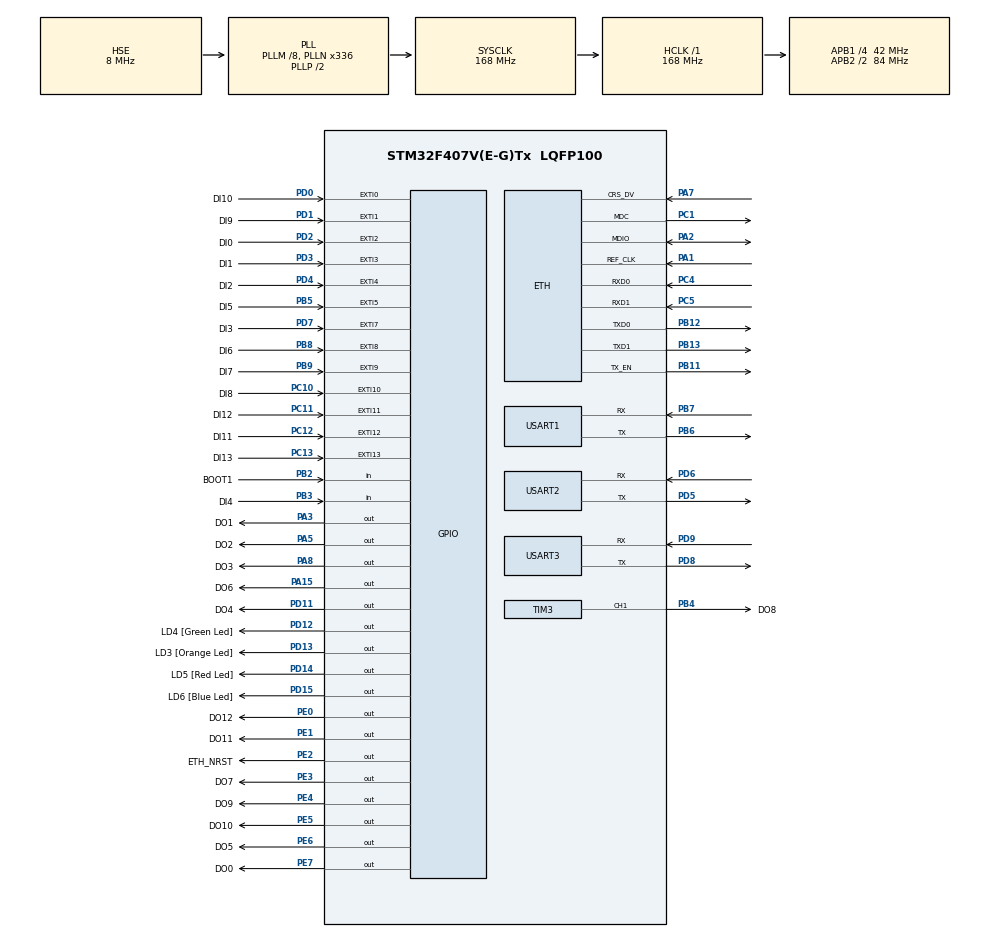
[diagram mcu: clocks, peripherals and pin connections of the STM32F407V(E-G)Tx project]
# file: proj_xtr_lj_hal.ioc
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Dma.Request0=USART1_RX
Dma.Request1=USART1_TX
Dma.Request2=USART2_RX
Dma.Request3=USART2_TX
Dma.Request4=USART3_RX
Dma.Request5=USART3_TX
Dma.USART1_RX.0.Direction=DMA_PERIPH_TO_MEMORY
Dma.USART1_RX.0.FIFOMode=DMA_FIFOMODE_DISABLE
Dma.USART1_RX.0.Instance=DMA2_Stream2
Dma.USART1_RX.0.MemDataAlignment=DMA_MDATAALIGN_BYTE
Dma.USART1_RX.0.MemInc=DMA_MINC_ENABLE
Dma.USART1_RX.0.Mode=DMA_NORMAL
Dma.USART1_RX.0.PeriphDataAlignment=DMA_PDATAALIGN_BYTE
Dma.USART1_RX.0.PeriphInc=DMA_PINC_DISABLE
Dma.USART1_RX.0.Priority=DMA_PRIORITY_LOW
Dma.USART1_TX.1.Direction=DMA_MEMORY_TO_PERIPH
Dma.USART1_TX.1.FIFOMode=DMA_FIFOMODE_DISABLE
Dma.USART1_TX.1.Instance=DMA2_Stream7
Dma.USART1_TX.1.MemDataAlignment=DMA_MDATAALIGN_BYTE
Dma.USART1_TX.1.MemInc=DMA_MINC_ENABLE
Dma.USART1_TX.1.Mode=DMA_NORMAL
Dma.USART1_TX.1.PeriphDataAlignment=DMA_PDATAALIGN_BYTE
Dma.USART1_TX.1.PeriphInc=DMA_PINC_DISABLE
Dma.USART1_TX.1.Priority=DMA_PRIORITY_LOW
Dma.USART2_RX.2.Direction=DMA_PERIPH_TO_MEMORY
Dma.USART2_RX.2.FIFOMode=DMA_FIFOMODE_DISABLE
Dma.USART2_RX.2.Instance=DMA1_Stream5
Dma.USART2_RX.2.MemDataAlignment=DMA_MDATAALIGN_BYTE
Dma.USART2_RX.2.MemInc=DMA_MINC_ENABLE
Dma.USART2_RX.2.Mode=DMA_NORMAL
Dma.USART2_RX.2.PeriphDataAlignment=DMA_PDATAALIGN_BYTE
Dma.USART2_RX.2.PeriphInc=DMA_PINC_DISABLE
Dma.USART2_RX.2.Priority=DMA_PRIORITY_LOW
Dma.USART2_TX.3.Direction=DMA_MEMORY_TO_PERIPH
Dma.USART2_TX.3.FIFOMode=DMA_FIFOMODE_DISABLE
Dma.USART2_TX.3.Instance=DMA1_Stream6
Dma.USART2_TX.3.MemDataAlignment=DMA_MDATAALIGN_BYTE
Dma.USART2_TX.3.MemInc=DMA_MINC_ENABLE
Dma.USART2_TX.3.Mode=DMA_NORMAL
Dma.USART2_TX.3.PeriphDataAlignment=DMA_PDATAALIGN_BYTE
Dma.USART2_TX.3.PeriphInc=DMA_PINC_DISABLE
Dma.USART2_TX.3.Priority=DMA_PRIORITY_LOW
Dma.USART3_RX.4.Direction=DMA_PERIPH_TO_MEMORY
Dma.USART3_RX.4.FIFOMode=DMA_FIFOMODE_DISABLE
Dma.USART3_RX.4.Instance=DMA1_Stream1
Dma.USART3_RX.4.MemDataAlignment=DMA_MDATAALIGN_BYTE
Dma.USART3_RX.4.MemInc=DMA_MINC_ENABLE
Dma.USART3_RX.4.Mode=DMA_NORMAL
Dma.USART3_RX.4.PeriphDataAlignment=DMA_PDATAALIGN_BYTE
Dma.USART3_RX.4.PeriphInc=DMA_PINC_DISABLE
Dma.USART3_RX.4.Priority=DMA_PRIORITY_LOW
Dma.USART3_TX.5.Direction=DMA_MEMORY_TO_PERIPH
Dma.USART3_TX.5.FIFOMode=DMA_FIFOMODE_DISABLE
Dma.USART3_TX.5.Instance=DMA1_Stream3
Dma.USART3_TX.5.MemDataAlignment=DMA_MDATAALIGN_BYTE
Dma.USART3_TX.5.MemInc=DMA_MINC_ENABLE
Dma.USART3_TX.5.Mode=DMA_NORMAL
Dma.USART3_TX.5.PeriphDataAlignment=DMA_PDATAALIGN_BYTE
Dma.USART3_TX.5.PeriphInc=DMA_PINC_DISABLE
Dma.USART3_TX.5.Priority=DMA_PRIORITY_LOW
ETH.MediaInterface=ETH_MEDIA_INTERFACE_RMII
ETH.PHY_Name_RMII=LAN8742A_PHY_ADDRESS
ETH.PhyAddress=1
FREERTOS.Tasks01=defaultTask,24,128,StartDefaultTask,Default,NULL,Dynamic,NULL,NULL;Blink,8,128,StartBlink,Default,NULL,Dynamic,NULL,NULL;KeepState,8,128,StartKeepState,Default,NULL,Dynamic,NULL,NULL
FREERTOS.configENABLE_FPU=1
Mcu.Family=STM32F4
Mcu.Name=STM32F407V(E-G)Tx
Mcu.Package=LQFP100
NVIC.DMA1_Stream1_IRQn=true\:0\:0\:false\:false\:true\:true\:false\:true
NVIC.DMA1_Stream3_IRQn=true\:0\:0\:false\:false\:true\:true\:false\:true
NVIC.DMA1_Stream5_IRQn=true\:0\:0\:false\:false\:true\:true\:false\:true
NVIC.DMA1_Stream6_IRQn=true\:0\:0\:false\:false\:true\:true\:false\:true
NVIC.DMA2_Stream2_IRQn=true\:0\:0\:false\:false\:true\:true\:false\:true
NVIC.DMA2_Stream7_IRQn=true\:0\:0\:false\:false\:true\:true\:false\:true
NVIC.EXTI0_IRQn=true\:1\:0\:true\:false\:true\:false\:true\:true
NVIC.EXTI15_10_IRQn=true\:1\:0\:true\:false\:true\:false\:true\:true
NVIC.EXTI1_IRQn=true\:1\:0\:true\:false\:true\:false\:true\:true
NVIC.EXTI2_IRQn=true\:2\:0\:true\:false\:true\:false\:true\:true
NVIC.EXTI3_IRQn=true\:2\:0\:true\:false\:true\:false\:true\:true
NVIC.EXTI4_IRQn=true\:2\:0\:true\:false\:true\:false\:true\:true
NVIC.EXTI9_5_IRQn=true\:2\:0\:true\:false\:true\:false\:true\:true
NVIC.PriorityGroup=NVIC_PRIORITYGROUP_4
NVIC.TIM3_IRQn=true\:0\:0\:true\:false\:true\:false\:true\:true
NVIC.TIM8_TRG_COM_TIM14_IRQn=true\:0\:0\:false\:false\:true\:false\:false\:true
NVIC.TimeBase=TIM8_TRG_COM_TIM14_IRQn
NVIC.TimeBaseIP=TIM14
NVIC.USART1_IRQn=true\:1\:0\:true\:false\:true\:false\:true\:true
NVIC.USART2_IRQn=true\:1\:0\:true\:false\:true\:false\:true\:true
NVIC.USART3_IRQn=true\:1\:0\:true\:false\:true\:false\:true\:true
PA1.Mode=RMII
PA1.Signal=ETH_REF_CLK
PA13.GPIO_Label=SWDIO
PA13.Mode=Serial_Wire
PA13.Signal=SYS_JTMS-SWDIO
PA14.GPIO_Label=SWCLK
PA14.Mode=Serial_Wire
PA14.Signal=SYS_JTCK-SWCLK
PA15.GPIO_Label=DO6
PA15.PinState=GPIO_PIN_SET
PA15.Signal=GPIO_Output
PA2.Mode=RMII
PA2.Signal=ETH_MDIO
PA3.GPIO_Label=DO1
PA3.PinState=GPIO_PIN_SET
PA3.Signal=GPIO_Output
PA5.GPIO_Label=DO2
PA5.PinState=GPIO_PIN_SET
PA5.Signal=GPIO_Output
PA7.Mode=RMII
PA7.Signal=ETH_CRS_DV
PA8.GPIO_Label=DO3
PA8.PinState=GPIO_PIN_SET
PA8.Signal=GPIO_Output
PB11.Mode=RMII
PB11.Signal=ETH_TX_EN
PB12.Mode=RMII
PB12.Signal=ETH_TXD0
PB13.Mode=RMII
PB13.Signal=ETH_TXD1
PB2.GPIO_Label=BOOT1
PB2.GPIO_Mode=GPIO_MODE_INPUT
PB2.GPIO_PuPd=GPIO_NOPULL
PB2.Signal=GPIO_Input
PB3.GPIO_Label=DI4
PB3.GPIO_PuPd=GPIO_PULLDOWN
PB3.Signal=GPIO_Input
PB4.GPIO_Label=DO8
PB4.GPIO_PuPd=GPIO_PULLUP
PB4.GPIO_Speed=GPIO_SPEED_FREQ_HIGH
PB4.Signal=S_TIM3_CH1
PB5.GPIO_Label=DI5
PB5.GPIO_ModeDefaultEXTI=GPIO_MODE_IT_RISING_FALLING
PB5.GPIO_PuPd=GPIO_PULLDOWN
PB5.Signal=GPXTI5
PB6.Mode=Asynchronous
PB6.Signal=USART1_TX
PB7.Mode=Asynchronous
PB7.Signal=USART1_RX
PB8.GPIO_Label=DI6
PB8.GPIO_ModeDefaultEXTI=GPIO_MODE_IT_RISING_FALLING
PB8.GPIO_PuPd=GPIO_PULLDOWN
PB8.Signal=GPXTI8
PB9.GPIO_Label=DI7
PB9.GPIO_ModeDefaultEXTI=GPIO_MODE_IT_RISING_FALLING
PB9.GPIO_PuPd=GPIO_PULLDOWN
PB9.Signal=GPXTI9
PC1.Mode=RMII
PC1.Signal=ETH_MDC
PC10.GPIO_Label=DI8
PC10.GPIO_ModeDefaultEXTI=GPIO_MODE_IT_RISING
PC10.GPIO_PuPd=GPIO_PULLDOWN
PC10.Signal=GPXTI10
PC11.GPIO_Label=DI12
PC11.GPIO_ModeDefaultEXTI=GPIO_MODE_IT_RISING
PC11.GPIO_PuPd=GPIO_PULLDOWN
PC11.Signal=GPXTI11
PC12.GPIO_Label=DI11
PC12.GPIO_ModeDefaultEXTI=GPIO_MODE_IT_RISING
PC12.GPIO_PuPd=GPIO_PULLDOWN
PC12.Signal=GPXTI12
PC13-ANTI_TAMP.GPIO_Label=DI13
PC13-ANTI_TAMP.GPIO_ModeDefaultEXTI=GPIO_MODE_IT_RISING
PC13-ANTI_TAMP.GPIO_PuPd=GPIO_PULLDOWN
PC13-ANTI_TAMP.Signal=GPXTI13
PC14-OSC32_IN.GPIO_Label=PC14-OSC32_IN
PC14-OSC32_IN.Mode=LSE-External-Oscillator
PC14-OSC32_IN.Signal=RCC_OSC32_IN
PC15-OSC32_OUT.GPIO_Label=PC15-OSC32_OUT
PC15-OSC32_OUT.Mode=LSE-External-Oscillator
PC15-OSC32_OUT.Signal=RCC_OSC32_OUT
PC4.Mode=RMII
PC4.Signal=ETH_RXD0
PC5.Mode=RMII
PC5.Signal=ETH_RXD1
PD0.GPIO_Label=DI10
PD0.GPIO_ModeDefaultEXTI=GPIO_MODE_IT_RISING
PD0.GPIO_PuPd=GPIO_PULLDOWN
PD0.Signal=GPXTI0
PD1.GPIO_Label=DI9
PD1.GPIO_ModeDefaultEXTI=GPIO_MODE_IT_RISING
PD1.GPIO_PuPd=GPIO_PULLDOWN
PD1.Signal=GPXTI1
PD11.GPIO_Label=DO4
PD11.PinState=GPIO_PIN_SET
PD11.Signal=GPIO_Output
PD12.GPIO_Label=LD4 [Green Led]
PD12.GPIO_PuPd=GPIO_NOPULL
PD12.GPIO_Speed=GPIO_SPEED_FREQ_LOW
PD12.Signal=GPIO_Output
PD13.GPIO_Label=LD3 [Orange Led]
PD13.GPIO_PuPd=GPIO_NOPULL
PD13.GPIO_Speed=GPIO_SPEED_FREQ_LOW
PD13.Signal=GPIO_Output
PD14.GPIO_Label=LD5 [Red Led]
PD14.GPIO_PuPd=GPIO_NOPULL
PD14.GPIO_Speed=GPIO_SPEED_FREQ_LOW
PD14.Signal=GPIO_Output
PD15.GPIO_Label=LD6 [Blue Led]
PD15.GPIO_PuPd=GPIO_NOPULL
PD15.GPIO_Speed=GPIO_SPEED_FREQ_LOW
PD15.Signal=GPIO_Output
PD2.GPIO_Label=DI0
PD2.GPIO_ModeDefaultEXTI=GPIO_MODE_IT_RISING_FALLING
PD2.GPIO_PuPd=GPIO_PULLDOWN
PD2.Signal=GPXTI2
PD3.GPIO_Label=DI1
PD3.GPIO_ModeDefaultEXTI=GPIO_MODE_IT_RISING_FALLING
PD3.GPIO_PuPd=GPIO_PULLDOWN
PD3.Signal=GPXTI3
PD4.GPIO_Label=DI2
PD4.GPIO_ModeDefaultEXTI=GPIO_MODE_IT_RISING_FALLING
PD4.GPIO_PuPd=GPIO_PULLDOWN
PD4.Signal=GPXTI4
PD5.Mode=Asynchronous
PD5.Signal=USART2_TX
PD6.Mode=Asynchronous
PD6.Signal=USART2_RX
PD7.GPIO_Label=DI3
PD7.GPIO_ModeDefaultEXTI=GPIO_MODE_IT_RISING_FALLING
PD7.GPIO_PuPd=GPIO_PULLDOWN
PD7.Signal=GPXTI7
PD8.Mode=Asynchronous
PD8.Signal=USART3_TX
PD9.Mode=Asynchronous
PD9.Signal=USART3_RX
PE0.GPIO_Label=DO12
PE0.PinState=GPIO_PIN_SET
PE0.Signal=GPIO_Output
PE1.GPIO_Label=DO11
PE1.PinState=GPIO_PIN_SET
PE1.Signal=GPIO_Output
PE2.GPIO_Label=ETH_NRST
PE2.PinState=GPIO_PIN_SET
PE2.Signal=GPIO_Output
PE3.GPIO_Label=DO7
PE3.PinState=GPIO_PIN_SET
PE3.Signal=GPIO_Output
PE4.GPIO_Label=DO9
PE4.PinState=GPIO_PIN_SET
PE4.Signal=GPIO_Output
PE5.GPIO_Label=DO10
PE5.PinState=GPIO_PIN_SET
PE5.Signal=GPIO_Output
PE6.GPIO_Label=DO5
PE6.PinState=GPIO_PIN_SET
PE6.Signal=GPIO_Output
PE7.GPIO_Label=DO0
PE7.PinState=GPIO_PIN_SET
PE7.Signal=GPIO_Output
PH0-OSC_IN.GPIO_Label=PH0-OSC_IN
PH0-OSC_IN.Mode=HSE-External-Oscillator
PH0-OSC_IN.Signal=RCC_OSC_IN
PH1-OSC_OUT.GPIO_Label=PH1-OSC_OUT
PH1-OSC_OUT.Mode=HSE-External-Oscillator
PH1-OSC_OUT.Signal=RCC_OSC_OUT
ProjectManager.HeapSize=0x200
ProjectManager.StackSize=0x400
ProjectManager.TargetToolchain=MDK-ARM V5.27
RCC.48MHZClocksFreq_Value=48000000
RCC.AHBFreq_Value=168000000
RCC.APB1CLKDivider=RCC_HCLK_DIV4
RCC.APB1Freq_Value=42000000
RCC.APB1TimFreq_Value=84000000
RCC.APB2CLKDivider=RCC_HCLK_DIV2
RCC.APB2Freq_Value=84000000
RCC.APB2TimFreq_Value=168000000
RCC.CortexFreq_Value=168000000
RCC.HCLKFreq_Value=168000000
RCC.HSE_VALUE=8000000
RCC.HSI_VALUE=16000000
RCC.PLLM=8
RCC.PLLN=336
RCC.PLLQ=7
RCC.PLLSourceVirtual=RCC_PLLSOURCE_HSE
RCC.SYSCLKFreq_VALUE=168000000
RCC.SYSCLKSource=RCC_SYSCLKSOURCE_PLLCLK
RCC.VCOOutputFreq_Value=336000000
SH.S_TIM3_CH1.0=TIM3_CH1,PWM Generation1 CH1
TIM3.Channel-PWM\ Generation1\ CH1=TIM_CHANNEL_1
TIM3.OCPolarity_1=TIM_OCPOLARITY_LOW
USART1.VirtualMode=VM_ASYNC
USART2.VirtualMode=VM_ASYNC
USART3.VirtualMode=VM_ASYNC
VP_FREERTOS_VS_CMSIS_V2.Mode=CMSIS_V2
VP_SYS_VS_tim14.Mode=TIM14
VP_TIM3_VS_ClockSourceINT.Mode=Internal
board=STM32F407G-DISC1

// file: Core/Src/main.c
/* USER CODE BEGIN Header */
/**
  ******************************************************************************
  * @file           : main.c
  * @brief          : Main program body
  ******************************************************************************
  * @attention
  *
  * <h2><center>&copy; Copyright (c) 2020 STMicroelectronics.
  * All rights reserved.</center></h2>
  *
  * This software component is licensed by ST under Ultimate Liberty license
  * SLA0044, the "License"; You may not use this file except in compliance with
  * the License. You may obtain a copy of the License at:
  *                             www.st.com/SLA0044
  *
  ******************************************************************************
  */
/* USER CODE END Header */
#include "main.h"
#include "cmsis_os.h"

ETH_HandleTypeDef heth;

TIM_HandleTypeDef htim3;

UART_HandleTypeDef huart1;
UART_HandleTypeDef huart2;
UART_HandleTypeDef huart3;
DMA_HandleTypeDef hdma_usart1_rx;
DMA_HandleTypeDef hdma_usart1_tx;
DMA_HandleTypeDef hdma_usart2_rx;
DMA_HandleTypeDef hdma_usart2_tx;
DMA_HandleTypeDef hdma_usart3_rx;
DMA_HandleTypeDef hdma_usart3_tx;

/* Definitions for defaultTask */
osThreadId_t defaultTaskHandle;
const osThreadAttr_t defaultTask_attributes = {
  .name = "defaultTask",
  .priority = (osPriority_t) osPriorityNormal,
  .stack_size = 128 * 4
};
/* Definitions for Blink */
osThreadId_t BlinkHandle;
const osThreadAttr_t Blink_attributes = {
  .name = "Blink",
  .priority = (osPriority_t) osPriorityLow,
  .stack_size = 128 * 4
};
/* Definitions for KeepState */
osThreadId_t KeepStateHandle;
const osThreadAttr_t KeepState_attributes = {
  .name = "KeepState",
  .priority = (osPriority_t) osPriorityLow,
  .stack_size = 128 * 4
};
/* USER CODE BEGIN PV */

uint8_t previous_command = 0;
uint8_t current_command = 0;
uint8_t UART_send_buffer[16];
uint8_t UART_recv_buffer[16];
uint8_t UART_field_buffer[16];
uint8_t ch;
int uart_recv_cnt = 0;
xSemaphoreHandle uart_A1_xSemaphore = NULL;
xSemaphoreHandle exti_xSemaphore = NULL;
portTickType time_origin;
volatile int pwm_count = 0;

osThreadId_t FieldHandle;
const osThreadAttr_t field_attributes = {
  .name = "FieldTask",
  .priority = (osPriority_t) osPriorityLow,
  .stack_size = 128 * 4
};
/* USER CODE END PV */

//xTaskHandle field_xHandle = NULL;

void SystemClock_Config(void);
static void MX_GPIO_Init(void);
static void MX_DMA_Init(void);
static void MX_USART1_UART_Init(void);
static void MX_USART2_UART_Init(void);
static void MX_USART3_UART_Init(void);
static void MX_TIM3_Init(void);
static void MX_ETH_Init(void);
void StartDefaultTask(void *argument);
void StartBlink(void *argument);
void StartKeepState(void *argument);

/* USER CODE BEGIN PFP */
HAL_StatusTypeDef process_command (void);
void field_task(void *argument);

/* USER CODE END PFP */

int main(void)
{

  /* MCU Configuration--------------------------------------------------------*/

  /* Reset of all peripherals, Initializes the Flash interface and the Systick. */
  HAL_Init();

  /* Configure the system clock */
  SystemClock_Config();

  /* Initialize all configured peripherals */
  MX_GPIO_Init();
  MX_DMA_Init();
  MX_USART1_UART_Init();
  MX_USART2_UART_Init();
  MX_USART3_UART_Init();
  MX_TIM3_Init();
  MX_ETH_Init();

  /* Init scheduler */
  osKernelInitialize();

  /* USER CODE BEGIN RTOS_SEMAPHORES */
  /* add semaphores, ... */
  vSemaphoreCreateBinary(uart_A1_xSemaphore);
	vSemaphoreCreateBinary(exti_xSemaphore);

  /* USER CODE END RTOS_SEMAPHORES */

  /* Create the thread(s) */
  /* creation of defaultTask */
  defaultTaskHandle = osThreadNew(StartDefaultTask, NULL, &defaultTask_attributes);

  /* creation of Blink */
  BlinkHandle = osThreadNew(StartBlink, NULL, &Blink_attributes);

  /* creation of KeepState */
  KeepStateHandle = osThreadNew(StartKeepState, NULL, &KeepState_attributes);

  /* Start scheduler */
  osKernelStart();

  /* We should never get here as control is now taken by the scheduler */
  /* Infinite loop */
  while (1)
  {

  }
}

void SystemClock_Config(void)
{
  RCC_OscInitTypeDef RCC_OscInitStruct = {0};
  RCC_ClkInitTypeDef RCC_ClkInitStruct = {0};

  /** Configure the main internal regulator output voltage
  */
  __HAL_RCC_PWR_CLK_ENABLE();
  __HAL_PWR_VOLTAGESCALING_CONFIG(PWR_REGULATOR_VOLTAGE_SCALE1);
  /** Initializes the RCC Oscillators according to the specified parameters
  * in the RCC_OscInitTypeDef structure.
  */
  RCC_OscInitStruct.OscillatorType = RCC_OSCILLATORTYPE_HSE;
  RCC_OscInitStruct.HSEState = RCC_HSE_ON;
  RCC_OscInitStruct.PLL.PLLState = RCC_PLL_ON;
  RCC_OscInitStruct.PLL.PLLSource = RCC_PLLSOURCE_HSE;
  RCC_OscInitStruct.PLL.PLLM = 8;
  RCC_OscInitStruct.PLL.PLLN = 336;
  RCC_OscInitStruct.PLL.PLLP = RCC_PLLP_DIV2;
  RCC_OscInitStruct.PLL.PLLQ = 7;
  if (HAL_RCC_OscConfig(&RCC_OscInitStruct) != HAL_OK)
  {
    Error_Handler();
  }
  /** Initializes the CPU, AHB and APB buses clocks
  */
  RCC_ClkInitStruct.ClockType = RCC_CLOCKTYPE_HCLK|RCC_CLOCKTYPE_SYSCLK
                              |RCC_CLOCKTYPE_PCLK1|RCC_CLOCKTYPE_PCLK2;
  RCC_ClkInitStruct.SYSCLKSource = RCC_SYSCLKSOURCE_PLLCLK;
  RCC_ClkInitStruct.AHBCLKDivider = RCC_SYSCLK_DIV1;
  RCC_ClkInitStruct.APB1CLKDivider = RCC_HCLK_DIV4;
  RCC_ClkInitStruct.APB2CLKDivider = RCC_HCLK_DIV2;

  if (HAL_RCC_ClockConfig(&RCC_ClkInitStruct, FLASH_LATENCY_5) != HAL_OK)
  {
    Error_Handler();
  }
}

static void MX_ETH_Init(void)
{

  heth.Instance = ETH;
  heth.Init.AutoNegotiation = ETH_AUTONEGOTIATION_ENABLE;
  heth.Init.PhyAddress = LAN8742A_PHY_ADDRESS;
  heth.Init.MACAddr[0] =   0x00;
  heth.Init.MACAddr[1] =   0x80;
  heth.Init.MACAddr[2] =   0xE1;
  heth.Init.MACAddr[3] =   0x00;
  heth.Init.MACAddr[4] =   0x00;
  heth.Init.MACAddr[5] =   0x00;
  heth.Init.RxMode = ETH_RXPOLLING_MODE;
  heth.Init.ChecksumMode = ETH_CHECKSUM_BY_HARDWARE;
  heth.Init.MediaInterface = ETH_MEDIA_INTERFACE_RMII;

  if (HAL_ETH_Init(&heth) != HAL_OK)
  {
    Error_Handler();
  }

}

static void MX_TIM3_Init(void)
{

  TIM_ClockConfigTypeDef sClockSourceConfig = {0};
  TIM_MasterConfigTypeDef sMasterConfig = {0};
  TIM_OC_InitTypeDef sConfigOC = {0};

  /* USER CODE BEGIN TIM3_Init 1 */

	SystemCoreClockUpdate();

  /* USER CODE END TIM3_Init 1 */
  htim3.Instance = TIM3;
  htim3.Init.Prescaler = (SystemCoreClock  / 2 / 10000 - 1);
  htim3.Init.CounterMode = TIM_COUNTERMODE_UP;
  htim3.Init.Period = 1333 - 1;
  htim3.Init.ClockDivision = TIM_CLOCKDIVISION_DIV1;
  htim3.Init.AutoReloadPreload = TIM_AUTORELOAD_PRELOAD_DISABLE;
  if (HAL_TIM_Base_Init(&htim3) != HAL_OK)
  {
    Error_Handler();
  }
  sClockSourceConfig.ClockSource = TIM_CLOCKSOURCE_INTERNAL;
  if (HAL_TIM_ConfigClockSource(&htim3, &sClockSourceConfig) != HAL_OK)
  {
    Error_Handler();
  }
  if (HAL_TIM_PWM_Init(&htim3) != HAL_OK)
  {
    Error_Handler();
  }
  sMasterConfig.MasterOutputTrigger = TIM_TRGO_RESET;
  sMasterConfig.MasterSlaveMode = TIM_MASTERSLAVEMODE_DISABLE;
  if (HAL_TIMEx_MasterConfigSynchronization(&htim3, &sMasterConfig) != HAL_OK)
  {
    Error_Handler();
  }
  sConfigOC.OCMode = TIM_OCMODE_PWM1;
  sConfigOC.Pulse = 0;
  sConfigOC.OCPolarity = TIM_OCPOLARITY_LOW;
  sConfigOC.OCFastMode = TIM_OCFAST_DISABLE;
  if (HAL_TIM_PWM_ConfigChannel(&htim3, &sConfigOC, TIM_CHANNEL_1) != HAL_OK)
  {
    Error_Handler();
  }
  HAL_TIM_MspPostInit(&htim3);

}

static void MX_USART1_UART_Init(void)
{

  huart1.Instance = USART1;
  huart1.Init.BaudRate = 115200;
  huart1.Init.WordLength = UART_WORDLENGTH_8B;
  huart1.Init.StopBits = UART_STOPBITS_1;
  huart1.Init.Parity = UART_PARITY_NONE;
  huart1.Init.Mode = UART_MODE_TX_RX;
  huart1.Init.HwFlowCtl = UART_HWCONTROL_NONE;
  huart1.Init.OverSampling = UART_OVERSAMPLING_16;
  if (HAL_UART_Init(&huart1) != HAL_OK)
  {
    Error_Handler();
  }

}

static void MX_USART2_UART_Init(void)
{

  huart2.Instance = USART2;
  huart2.Init.BaudRate = 115200;
  huart2.Init.WordLength = UART_WORDLENGTH_8B;
  huart2.Init.StopBits = UART_STOPBITS_1;
  huart2.Init.Parity = UART_PARITY_NONE;
  huart2.Init.Mode = UART_MODE_TX_RX;
  huart2.Init.HwFlowCtl = UART_HWCONTROL_NONE;
  huart2.Init.OverSampling = UART_OVERSAMPLING_16;
  if (HAL_UART_Init(&huart2) != HAL_OK)
  {
    Error_Handler();
  }

}

static void MX_USART3_UART_Init(void)
{

  huart3.Instance = USART3;
  huart3.Init.BaudRate = 115200;
  huart3.Init.WordLength = UART_WORDLENGTH_8B;
  huart3.Init.StopBits = UART_STOPBITS_1;
  huart3.Init.Parity = UART_PARITY_NONE;
  huart3.Init.Mode = UART_MODE_TX_RX;
  huart3.Init.HwFlowCtl = UART_HWCONTROL_NONE;
  huart3.Init.OverSampling = UART_OVERSAMPLING_16;
  if (HAL_UART_Init(&huart3) != HAL_OK)
  {
    Error_Handler();
  }

}

static void MX_DMA_Init(void)
{

  /* DMA controller clock enable */
  __HAL_RCC_DMA2_CLK_ENABLE();
  __HAL_RCC_DMA1_CLK_ENABLE();

  /* DMA interrupt init */
  /* DMA1_Stream1_IRQn interrupt configuration */
  HAL_NVIC_SetPriority(DMA1_Stream1_IRQn, 0, 0);
  HAL_NVIC_EnableIRQ(DMA1_Stream1_IRQn);
  /* DMA1_Stream3_IRQn interrupt configuration */
  HAL_NVIC_SetPriority(DMA1_Stream3_IRQn, 0, 0);
  HAL_NVIC_EnableIRQ(DMA1_Stream3_IRQn);
  /* DMA1_Stream5_IRQn interrupt configuration */
  HAL_NVIC_SetPriority(DMA1_Stream5_IRQn, 0, 0);
  HAL_NVIC_EnableIRQ(DMA1_Stream5_IRQn);
  /* DMA1_Stream6_IRQn interrupt configuration */
  HAL_NVIC_SetPriority(DMA1_Stream6_IRQn, 0, 0);
  HAL_NVIC_EnableIRQ(DMA1_Stream6_IRQn);
  /* DMA2_Stream2_IRQn interrupt configuration */
  HAL_NVIC_SetPriority(DMA2_Stream2_IRQn, 0, 0);
  HAL_NVIC_EnableIRQ(DMA2_Stream2_IRQn);
  /* DMA2_Stream7_IRQn interrupt configuration */
  HAL_NVIC_SetPriority(DMA2_Stream7_IRQn, 0, 0);
  HAL_NVIC_EnableIRQ(DMA2_Stream7_IRQn);

}

static void MX_GPIO_Init(void)
{
  GPIO_InitTypeDef GPIO_InitStruct = {0};

  /* GPIO Ports Clock Enable */
  __HAL_RCC_GPIOE_CLK_ENABLE();
  __HAL_RCC_GPIOC_CLK_ENABLE();
  __HAL_RCC_GPIOH_CLK_ENABLE();
  __HAL_RCC_GPIOA_CLK_ENABLE();
  __HAL_RCC_GPIOB_CLK_ENABLE();
  __HAL_RCC_GPIOD_CLK_ENABLE();

  /*Configure GPIO pin Output Level */
  HAL_GPIO_WritePin(GPIOE, ETH_NRST_Pin|DO7_Pin|DO9_Pin|DO10_Pin
                          |DO5_Pin|DO0_Pin|DO12_Pin|DO11_Pin, GPIO_PIN_SET);

  /*Configure GPIO pin Output Level */
  HAL_GPIO_WritePin(GPIOA, DO1_Pin|DO2_Pin|DO3_Pin|DO6_Pin, GPIO_PIN_SET);

  /*Configure GPIO pin Output Level */
  HAL_GPIO_WritePin(DO4_GPIO_Port, DO4_Pin, GPIO_PIN_SET);

  /*Configure GPIO pin Output Level */
  HAL_GPIO_WritePin(GPIOD, LD4_Pin|LD3_Pin|LD5_Pin|LD6_Pin, GPIO_PIN_RESET);

  /*Configure GPIO pins : ETH_NRST_Pin DO7_Pin DO9_Pin DO10_Pin
                           DO5_Pin DO0_Pin DO12_Pin DO11_Pin */
  GPIO_InitStruct.Pin = ETH_NRST_Pin|DO7_Pin|DO9_Pin|DO10_Pin
                          |DO5_Pin|DO0_Pin|DO12_Pin|DO11_Pin;
  GPIO_InitStruct.Mode = GPIO_MODE_OUTPUT_PP;
  GPIO_InitStruct.Pull = GPIO_NOPULL;
  GPIO_InitStruct.Speed = GPIO_SPEED_FREQ_LOW;
  HAL_GPIO_Init(GPIOE, &GPIO_InitStruct);

  /*Configure GPIO pins : DI13_Pin DI8_Pin DI12_Pin DI11_Pin */
  GPIO_InitStruct.Pin = DI13_Pin|DI8_Pin|DI12_Pin|DI11_Pin;
  GPIO_InitStruct.Mode = GPIO_MODE_IT_RISING;
  GPIO_InitStruct.Pull = GPIO_PULLDOWN;
  HAL_GPIO_Init(GPIOC, &GPIO_InitStruct);

  /*Configure GPIO pins : DO1_Pin DO2_Pin DO3_Pin DO6_Pin */
  GPIO_InitStruct.Pin = DO1_Pin|DO2_Pin|DO3_Pin|DO6_Pin;
  GPIO_InitStruct.Mode = GPIO_MODE_OUTPUT_PP;
  GPIO_InitStruct.Pull = GPIO_NOPULL;
  GPIO_InitStruct.Speed = GPIO_SPEED_FREQ_LOW;
  HAL_GPIO_Init(GPIOA, &GPIO_InitStruct);

  /*Configure GPIO pin : BOOT1_Pin */
  GPIO_InitStruct.Pin = BOOT1_Pin;
  GPIO_InitStruct.Mode = GPIO_MODE_INPUT;
  GPIO_InitStruct.Pull = GPIO_NOPULL;
  HAL_GPIO_Init(BOOT1_GPIO_Port, &GPIO_InitStruct);

  /*Configure GPIO pins : DO4_Pin LD4_Pin LD3_Pin LD5_Pin
                           LD6_Pin */
  GPIO_InitStruct.Pin = DO4_Pin|LD4_Pin|LD3_Pin|LD5_Pin
                          |LD6_Pin;
  GPIO_InitStruct.Mode = GPIO_MODE_OUTPUT_PP;
  GPIO_InitStruct.Pull = GPIO_NOPULL;
  GPIO_InitStruct.Speed = GPIO_SPEED_FREQ_LOW;
  HAL_GPIO_Init(GPIOD, &GPIO_InitStruct);

  /*Configure GPIO pins : DI10_Pin DI9_Pin */
  GPIO_InitStruct.Pin = DI10_Pin|DI9_Pin;
  GPIO_InitStruct.Mode = GPIO_MODE_IT_RISING;
  GPIO_InitStruct.Pull = GPIO_PULLDOWN;
  HAL_GPIO_Init(GPIOD, &GPIO_InitStruct);

  /*Configure GPIO pins : DI0_Pin DI1_Pin DI2_Pin DI3_Pin */
  GPIO_InitStruct.Pin = DI0_Pin|DI1_Pin|DI2_Pin|DI3_Pin;
  GPIO_InitStruct.Mode = GPIO_MODE_IT_RISING_FALLING;
  GPIO_InitStruct.Pull = GPIO_PULLDOWN;
  HAL_GPIO_Init(GPIOD, &GPIO_InitStruct);

  /*Configure GPIO pin : DI4_Pin */
  GPIO_InitStruct.Pin = DI4_Pin;
  GPIO_InitStruct.Mode = GPIO_MODE_INPUT;
  GPIO_InitStruct.Pull = GPIO_PULLDOWN;
  HAL_GPIO_Init(DI4_GPIO_Port, &GPIO_InitStruct);

  /*Configure GPIO pins : DI5_Pin DI6_Pin DI7_Pin */
  GPIO_InitStruct.Pin = DI5_Pin|DI6_Pin|DI7_Pin;
  GPIO_InitStruct.Mode = GPIO_MODE_IT_RISING_FALLING;
  GPIO_InitStruct.Pull = GPIO_PULLDOWN;
  HAL_GPIO_Init(GPIOB, &GPIO_InitStruct);

  /* EXTI interrupt init*/
  HAL_NVIC_SetPriority(EXTI0_IRQn, 1, 0);
  HAL_NVIC_EnableIRQ(EXTI0_IRQn);

  HAL_NVIC_SetPriority(EXTI1_IRQn, 1, 0);
  HAL_NVIC_EnableIRQ(EXTI1_IRQn);

  HAL_NVIC_SetPriority(EXTI2_IRQn, 2, 0);
  HAL_NVIC_EnableIRQ(EXTI2_IRQn);

  HAL_NVIC_SetPriority(EXTI3_IRQn, 2, 0);
  HAL_NVIC_EnableIRQ(EXTI3_IRQn);

  HAL_NVIC_SetPriority(EXTI4_IRQn, 2, 0);
  HAL_NVIC_EnableIRQ(EXTI4_IRQn);

  HAL_NVIC_SetPriority(EXTI9_5_IRQn, 2, 0);
  HAL_NVIC_EnableIRQ(EXTI9_5_IRQn);

  HAL_NVIC_SetPriority(EXTI15_10_IRQn, 1, 0);
  HAL_NVIC_EnableIRQ(EXTI15_10_IRQn);

}

/* USER CODE BEGIN 4 */

void HAL_GPIO_EXTI_Callback(uint16_t GPIO_Pin)
{
	portBASE_TYPE xHigherPriorityTaskWoken;
  if(GPIO_Pin == GPIO_PIN_2 || GPIO_Pin == GPIO_PIN_3 || GPIO_Pin == GPIO_PIN_4 || GPIO_Pin == GPIO_PIN_5 || GPIO_Pin == GPIO_PIN_7 || GPIO_Pin == GPIO_PIN_8 || GPIO_Pin == GPIO_PIN_9)
	{
//		if(exti_lock == 0) {
//			exti_lock = 1;
//			process_command();
//		HAL_GPIO_TogglePin(GPIOD, LD5_Pin);
//			exti_lock = 0;
	}
	else if (GPIO_Pin == GPIO_PIN_0) //DI10 PD
	{
		if(HAL_GPIO_ReadPin(GPIOD, GPIO_PIN_0) == 1)
		{
			HAL_GPIO_WritePin(GPIOA, GPIO_PIN_5, GPIO_PIN_RESET);
		}
	}
	else if (GPIO_Pin == GPIO_PIN_1) //DI9	PD
	{
		if(HAL_GPIO_ReadPin(GPIOD, GPIO_PIN_1) == 1)
		{
			HAL_GPIO_WritePin(GPIOA, GPIO_PIN_3, GPIO_PIN_RESET);
		}
	}
	else if (GPIO_Pin == GPIO_PIN_10) //DI8	PC
	{
		if(HAL_GPIO_ReadPin(GPIOC, GPIO_PIN_10) == 1)
		{
			HAL_GPIO_WritePin(GPIOE, GPIO_PIN_7, GPIO_PIN_RESET);
		}
	}
	else if (GPIO_Pin == GPIO_PIN_11) //DI12	PC
	{
		if(HAL_GPIO_ReadPin(GPIOC, GPIO_PIN_11) == 1)
		{
			HAL_GPIO_WritePin(GPIOD, GPIO_PIN_11, GPIO_PIN_RESET);
		}
	}
	else if (GPIO_Pin == GPIO_PIN_12) //DI11	PC
	{
		if(HAL_GPIO_ReadPin(GPIOC, GPIO_PIN_12) == 1)
		{
			HAL_GPIO_WritePin(GPIOA, GPIO_PIN_8, GPIO_PIN_RESET);

		}
	}
	else if (GPIO_Pin == GPIO_PIN_13) //DI13	PC
	{
		if(HAL_GPIO_ReadPin(GPIOC, GPIO_PIN_13) == 1)
		{
			HAL_GPIO_WritePin(GPIOE, GPIO_PIN_6, GPIO_PIN_RESET);
			xSemaphoreGiveFromISR( exti_xSemaphore, &xHigherPriorityTaskWoken );
		}
	}
}

HAL_StatusTypeDef process_command (void)
{
	unsigned int code_verify;
	unsigned int frame_verify;

	switch (current_command) {
		case 0x00:
//			HAL_GPIO_TogglePin(GPIOD, LD6_Pin);
//			if(HAL_UART_Transmit_DMA(&huart1, (uint8_t *)&UART_send_buffer, 13) != HAL_OK)
//			{
//			}
			HAL_GPIO_WritePin(GPIOA, GPIO_PIN_3| GPIO_PIN_5| GPIO_PIN_8| GPIO_PIN_15, GPIO_PIN_SET);
			HAL_GPIO_WritePin(GPIOD, GPIO_PIN_11, GPIO_PIN_SET);
			HAL_GPIO_WritePin(GPIOE, GPIO_PIN_0| GPIO_PIN_1| GPIO_PIN_3| GPIO_PIN_4| GPIO_PIN_5| GPIO_PIN_6| GPIO_PIN_7, GPIO_PIN_SET);
			HAL_TIM_PWM_Stop(&htim3, TIM_CHANNEL_1);
			__HAL_TIM_SET_COMPARE(&htim3, TIM_CHANNEL_1, 0);
	//				pwm_count = 0;
			if( FieldHandle != NULL ) {
				osThreadTerminate( FieldHandle );
			}
			return HAL_OK;

		case 0xff:
			HAL_GPIO_WritePin(GPIOA, GPIO_PIN_3| GPIO_PIN_5| GPIO_PIN_8| GPIO_PIN_15, GPIO_PIN_SET);
			HAL_GPIO_WritePin(GPIOD, GPIO_PIN_11, GPIO_PIN_SET);
			HAL_GPIO_WritePin(GPIOE, GPIO_PIN_0| GPIO_PIN_1| GPIO_PIN_3| GPIO_PIN_4| GPIO_PIN_5| GPIO_PIN_6| GPIO_PIN_7, GPIO_PIN_SET);
			HAL_TIM_PWM_Stop(&htim3, TIM_CHANNEL_1);
			__HAL_TIM_SET_COMPARE(&htim3, TIM_CHANNEL_1, 0);
	//				pwm_count = 0;
			if( FieldHandle != NULL ) {
				osThreadTerminate( FieldHandle );
			}
			return HAL_OK;

		case 0x01:
			if( FieldHandle != NULL ) {
				osThreadTerminate( FieldHandle );
			}
			HAL_TIM_PWM_Stop(&htim3, TIM_CHANNEL_1);
			__HAL_TIM_SET_COMPARE(&htim3, TIM_CHANNEL_1, 0);
	//				pwm_count = 0;

				//config DO6/7/9/10/11/12
			HAL_GPIO_WritePin(GPIOA, GPIO_PIN_15, GPIO_PIN_SET);
			HAL_GPIO_WritePin(GPIOE, GPIO_PIN_1| GPIO_PIN_3| GPIO_PIN_4, GPIO_PIN_SET);
			HAL_GPIO_WritePin(GPIOE, GPIO_PIN_0| GPIO_PIN_5, GPIO_PIN_RESET);

			if (xSemaphoreTake( uart_A1_xSemaphore, 10000) == pdTRUE) {
					// hand shake
					// fill buffer as in tab3B1
					// function start: repeated code of hand shake sent tab3B1
					UART_send_buffer[0] = 0xA6;
					UART_send_buffer[1] = 0x0D;
					UART_send_buffer[2] = 0xAA;
					//https://zhidao.baidu.com/question/1638675882443131580.html?qbpn=2_2&tx=&word=%E4%BB%8E%E4%B8%80%E4%B8%AA16%E4%BD%8D%E5%8F%98%E9%87%8F%E4%B8%AD%E5%8F%96%E5%87%BA%E9%AB%988%E4%BD%8D%E5%92%8C%E4%BD%8E8%E4%BD%8D%EF%BC%8C%E6%B1%82C%E8%AF%AD%E8%A8%80%E7%A8%8B%E5%BA%8F%EF%BC%9F&fr=newsearchlist
					code_verify = (UART_recv_buffer[3] + UART_recv_buffer[4]) * UART_recv_buffer[5];
					UART_send_buffer[3] = code_verify & 0xff;
					UART_send_buffer[4] = (code_verify >> 8) & 0xff;
					UART_send_buffer[5] = (code_verify >> 16) & 0xff;
					UART_send_buffer[6] = (code_verify >> 24) & 0xff;
					UART_send_buffer[7] = 0x0B;
					UART_send_buffer[8] = 0x00;
					UART_send_buffer[9] = 0x00;
					UART_send_buffer[10] = 0x00;
					UART_send_buffer[11] = 0x00;
					frame_verify = UART_send_buffer[2] + UART_send_buffer[3] + UART_send_buffer[4] + UART_send_buffer[5] + \
											   UART_send_buffer[6] + UART_send_buffer[7] + UART_send_buffer[8] + UART_send_buffer[9] + \
												 UART_send_buffer[10];
					UART_send_buffer[12] = frame_verify & 0xff;
					UART_send_buffer[13] = 0x86;

					// send buffer
					HAL_UART_Transmit_DMA(&huart1, (uint8_t *)&UART_send_buffer, 13);   //choose uart line
					if (xSemaphoreTake( exti_xSemaphore, 10000) == pdTRUE) {
						time_origin = xTaskGetTickCount() * portTICK_RATE_MS;
						FieldHandle = osThreadNew(field_task, NULL, &field_attributes);
					}
					else {
						//error message
					}
			}
			return HAL_OK;

		case 0x02:
			if( FieldHandle != NULL ) {
				osThreadTerminate( FieldHandle );
			}
			HAL_TIM_PWM_Stop(&htim3, TIM_CHANNEL_1);
			__HAL_TIM_SET_AUTORELOAD(&htim3, 1333 - 1);
			__HAL_TIM_SET_COMPARE(&htim3, TIM_CHANNEL_1, 100 - 1);
			HAL_TIM_PWM_Start(&htim3, TIM_CHANNEL_1);
	//				pwm_count = 0;

		//config DO6/7/9/10/11/12
			HAL_GPIO_WritePin(GPIOA, GPIO_PIN_15, GPIO_PIN_SET);
			HAL_GPIO_WritePin(GPIOE, GPIO_PIN_0| GPIO_PIN_1| GPIO_PIN_3| GPIO_PIN_4, GPIO_PIN_SET);
			HAL_GPIO_WritePin(GPIOE, GPIO_PIN_5, GPIO_PIN_RESET);

			if (xSemaphoreTake( uart_A1_xSemaphore, 10000) == pdTRUE) {
					// hand shake
					// fill buffer as in tab3B1
					// function start: repeated code of hand shake sent tab3B1
					UART_send_buffer[0] = 0xA6;
					UART_send_buffer[1] = 0x0D;
					UART_send_buffer[2] = 0xAA;
					//https://zhidao.baidu.com/question/1638675882443131580.html?qbpn=2_2&tx=&word=%E4%BB%8E%E4%B8%80%E4%B8%AA16%E4%BD%8D%E5%8F%98%E9%87%8F%E4%B8%AD%E5%8F%96%E5%87%BA%E9%AB%988%E4%BD%8D%E5%92%8C%E4%BD%8E8%E4%BD%8D%EF%BC%8C%E6%B1%82C%E8%AF%AD%E8%A8%80%E7%A8%8B%E5%BA%8F%EF%BC%9F&fr=newsearchlist
					code_verify = (UART_recv_buffer[3] + UART_recv_buffer[4]) * UART_recv_buffer[5];
					UART_send_buffer[3] = code_verify & 0xff;
					UART_send_buffer[4] = (code_verify >> 8) & 0xff;
					UART_send_buffer[5] = (code_verify >> 16) & 0xff;
					UART_send_buffer[6] = (code_verify >> 24) & 0xff;
					UART_send_buffer[7] = 0x0B;
					UART_send_buffer[8] = 0x00;
					UART_send_buffer[9] = 0x00;
					UART_send_buffer[10] = 0x00;
					UART_send_buffer[11] = 0x00;
					frame_verify = UART_send_buffer[2] + UART_send_buffer[3] + UART_send_buffer[4] + UART_send_buffer[5] + \
											   UART_send_buffer[6] + UART_send_buffer[7] + UART_send_buffer[8] + UART_send_buffer[9] + \
												 UART_send_buffer[10];
					UART_send_buffer[12] = frame_verify & 0xff;
					UART_send_buffer[13] = 0x86;

					// send buffer
					HAL_UART_Transmit_DMA(&huart1, (uint8_t *)&UART_send_buffer, 13);   //choose uart line

					if (xSemaphoreTake( exti_xSemaphore, 10000) == pdTRUE) {
						time_origin = xTaskGetTickCount() * portTICK_RATE_MS;
						FieldHandle = osThreadNew(field_task, NULL, &field_attributes);
					}
					else {
						//error message
					}
			}
			return HAL_OK;

		case 0x03:
			if( FieldHandle != NULL ) {
				osThreadTerminate( FieldHandle );
			}
			HAL_TIM_PWM_Stop(&htim3, TIM_CHANNEL_1);
			__HAL_TIM_SET_AUTORELOAD(&htim3, 1333 - 1);
			__HAL_TIM_SET_COMPARE(&htim3, TIM_CHANNEL_1, 100 - 1);
			HAL_TIM_PWM_Start(&htim3, TIM_CHANNEL_1);
	//				pwm_count = 0;

		//config DO6/7/9/10/11/12
			HAL_GPIO_WritePin(GPIOA, GPIO_PIN_15, GPIO_PIN_SET);
			HAL_GPIO_WritePin(GPIOE, GPIO_PIN_0| GPIO_PIN_4|GPIO_PIN_5, GPIO_PIN_SET);
			HAL_GPIO_WritePin(GPIOE,  GPIO_PIN_1| GPIO_PIN_3, GPIO_PIN_RESET);

			if (xSemaphoreTake( uart_A1_xSemaphore,10000) == pdTRUE) {
					// hand shake
					// fill buffer as in tab3B1
					// function start: repeated code of hand shake sent tab3B1
					UART_send_buffer[0] = 0xA6;
					UART_send_buffer[1] = 0x0D;
					UART_send_buffer[2] = 0xAA;
					//https://zhidao.baidu.com/question/1638675882443131580.html?qbpn=2_2&tx=&word=%E4%BB%8E%E4%B8%80%E4%B8%AA16%E4%BD%8D%E5%8F%98%E9%87%8F%E4%B8%AD%E5%8F%96%E5%87%BA%E9%AB%988%E4%BD%8D%E5%92%8C%E4%BD%8E8%E4%BD%8D%EF%BC%8C%E6%B1%82C%E8%AF%AD%E8%A8%80%E7%A8%8B%E5%BA%8F%EF%BC%9F&fr=newsearchlist
					code_verify = (UART_recv_buffer[3] + UART_recv_buffer[4]) * UART_recv_buffer[5];
					UART_send_buffer[3] = code_verify & 0xff;
					UART_send_buffer[4] = (code_verify >> 8) & 0xff;
					UART_send_buffer[5] = (code_verify >> 16) & 0xff;
					UART_send_buffer[6] = (code_verify >> 24) & 0xff;
					UART_send_buffer[7] = 0x0B;
					UART_send_buffer[8] = 0x00;
					UART_send_buffer[9] = 0x00;
					UART_send_buffer[10] = 0x00;
					UART_send_buffer[11] = 0x00;
					frame_verify = UART_send_buffer[2] + UART_send_buffer[3] + UART_send_buffer[4] + UART_send_buffer[5] + \
											   UART_send_buffer[6] + UART_send_buffer[7] + UART_send_buffer[8] + UART_send_buffer[9] + \
												 UART_send_buffer[10];
					UART_send_buffer[12] = frame_verify & 0xff;
					UART_send_buffer[13] = 0x86;

					// send buffer
					HAL_UART_Transmit_DMA(&huart1, (uint8_t *)&UART_send_buffer, 13);   //choose uart line

					if (xSemaphoreTake( exti_xSemaphore, 10000) == pdTRUE) {
						time_origin = xTaskGetTickCount() * portTICK_RATE_MS;
						FieldHandle = osThreadNew(field_task, NULL, &field_attributes);
					}
					else {
						//error message
					}
			}
			return HAL_OK;

		case 0x04:
			if( FieldHandle != NULL ) {
				osThreadTerminate( FieldHandle );
			}
			HAL_TIM_PWM_Stop(&htim3, TIM_CHANNEL_1);
			__HAL_TIM_SET_AUTORELOAD(&htim3, 1333 - 1);
			__HAL_TIM_SET_COMPARE(&htim3, TIM_CHANNEL_1, 100 - 1);
			HAL_TIM_PWM_Start(&htim3, TIM_CHANNEL_1);
	//				pwm_count = 0;

		//config DO6/7/9/10/11/12
			HAL_GPIO_WritePin(GPIOA, GPIO_PIN_15, GPIO_PIN_SET);
			HAL_GPIO_WritePin(GPIOE, GPIO_PIN_0|  GPIO_PIN_3|GPIO_PIN_4|GPIO_PIN_5, GPIO_PIN_SET);
			HAL_GPIO_WritePin(GPIOE,  GPIO_PIN_1, GPIO_PIN_RESET);

			if (xSemaphoreTake( uart_A1_xSemaphore,10000) == pdTRUE) {
					// hand shake
					// fill buffer as in tab3B1
					// function start: repeated code of hand shake sent tab3B1
					UART_send_buffer[0] = 0xA6;
					UART_send_buffer[1] = 0x0D;
					UART_send_buffer[2] = 0xAA;
					//https://zhidao.baidu.com/question/1638675882443131580.html?qbpn=2_2&tx=&word=%E4%BB%8E%E4%B8%80%E4%B8%AA16%E4%BD%8D%E5%8F%98%E9%87%8F%E4%B8%AD%E5%8F%96%E5%87%BA%E9%AB%988%E4%BD%8D%E5%92%8C%E4%BD%8E8%E4%BD%8D%EF%BC%8C%E6%B1%82C%E8%AF%AD%E8%A8%80%E7%A8%8B%E5%BA%8F%EF%BC%9F&fr=newsearchlist
					code_verify = (UART_recv_buffer[3] + UART_recv_buffer[4]) * UART_recv_buffer[5];
					UART_send_buffer[3] = code_verify & 0xff;
					UART_send_buffer[4] = (code_verify >> 8) & 0xff;
					UART_send_buffer[5] = (code_verify >> 16) & 0xff;
					UART_send_buffer[6] = (code_verify >> 24) & 0xff;
					UART_send_buffer[7] = 0x0B;
					UART_send_buffer[8] = 0x00;
					UART_send_buffer[9] = 0x00;
					UART_send_buffer[10] = 0x00;
					UART_send_buffer[11] = 0x00;
					frame_verify = UART_send_buffer[2] + UART_send_buffer[3] + UART_send_buffer[4] + UART_send_buffer[5] + \
											   UART_send_buffer[6] + UART_send_buffer[7] + UART_send_buffer[8] + UART_send_buffer[9] + \
												 UART_send_buffer[10];
					UART_send_buffer[12] = frame_verify & 0xff;
					UART_send_buffer[13] = 0x86;

					// send buffer
					HAL_UART_Transmit_DMA(&huart1, (uint8_t *)&UART_send_buffer, 13);   //choose uart line

					if (xSemaphoreTake( exti_xSemaphore, 10000) == pdTRUE) {
						time_origin = xTaskGetTickCount() * portTICK_RATE_MS;
						FieldHandle = osThreadNew(field_task, NULL, &field_attributes);
					}
					else {
						//error message
					}
			}

			return HAL_OK;

		case 0x05:
			if( FieldHandle != NULL ) {
				osThreadTerminate( FieldHandle );
			}
			HAL_TIM_PWM_Stop(&htim3, TIM_CHANNEL_1);
			__HAL_TIM_SET_AUTORELOAD(&htim3, 1333 - 1);
			__HAL_TIM_SET_COMPARE(&htim3, TIM_CHANNEL_1, 100 - 1);
			HAL_TIM_PWM_Start(&htim3, TIM_CHANNEL_1);
	//				pwm_count = 0;

		//config DO6/7/9/10/11/12
			HAL_GPIO_WritePin(GPIOA, GPIO_PIN_15, GPIO_PIN_SET);
			HAL_GPIO_WritePin(GPIOE, GPIO_PIN_0|  GPIO_PIN_3|GPIO_PIN_5, GPIO_PIN_SET);
			HAL_GPIO_WritePin(GPIOE,  GPIO_PIN_1|GPIO_PIN_4, GPIO_PIN_RESET);

			if (xSemaphoreTake( uart_A1_xSemaphore,10000) == pdTRUE) {
					// hand shake
					// fill buffer as in tab3B1
					// function start: repeated code of hand shake sent tab3B1
					UART_send_buffer[0] = 0xA6;
					UART_send_buffer[1] = 0x0D;
					UART_send_buffer[2] = 0xAA;
					//https://zhidao.baidu.com/question/1638675882443131580.html?qbpn=2_2&tx=&word=%E4%BB%8E%E4%B8%80%E4%B8%AA16%E4%BD%8D%E5%8F%98%E9%87%8F%E4%B8%AD%E5%8F%96%E5%87%BA%E9%AB%988%E4%BD%8D%E5%92%8C%E4%BD%8E8%E4%BD%8D%EF%BC%8C%E6%B1%82C%E8%AF%AD%E8%A8%80%E7%A8%8B%E5%BA%8F%EF%BC%9F&fr=newsearchlist
					code_verify = (UART_recv_buffer[3] + UART_recv_buffer[4]) * UART_recv_buffer[5];
					UART_send_buffer[3] = code_verify & 0xff;
					UART_send_buffer[4] = (code_verify >> 8) & 0xff;
					UART_send_buffer[5] = (code_verify >> 16) & 0xff;
					UART_send_buffer[6] = (code_verify >> 24) & 0xff;
					UART_send_buffer[7] = 0x0B;
					UART_send_buffer[8] = 0x00;
					UART_send_buffer[9] = 0x00;
					UART_send_buffer[10] = 0x00;
					UART_send_buffer[11] = 0x00;
					frame_verify = UART_send_buffer[2] + UART_send_buffer[3] + UART_send_buffer[4] + UART_send_buffer[5] + \
											   UART_send_buffer[6] + UART_send_buffer[7] + UART_send_buffer[8] + UART_send_buffer[9] + \
												 UART_send_buffer[10];
					UART_send_buffer[12] = frame_verify & 0xff;
					UART_send_buffer[13] = 0x86;

					// send buffer
					HAL_UART_Transmit_DMA(&huart1, (uint8_t *)&UART_send_buffer, 13);   //choose uart line

					if (xSemaphoreTake( exti_xSemaphore, 10000) == pdTRUE) {
						time_origin = xTaskGetTickCount() * portTICK_RATE_MS;
						FieldHandle = osThreadNew(field_task, NULL, &field_attributes);
					}
					else {
						//error message
					}
			}

			return HAL_OK;

		case 0x06:
			if( FieldHandle != NULL ) {
				osThreadTerminate( FieldHandle );
			}
			HAL_TIM_PWM_Stop(&htim3, TIM_CHANNEL_1);
			__HAL_TIM_SET_AUTORELOAD(&htim3, 1500 - 1);
			__HAL_TIM_SET_COMPARE(&htim3, TIM_CHANNEL_1, 100 - 1);
			HAL_TIM_PWM_Start(&htim3, TIM_CHANNEL_1);
	//				pwm_count = 0;

		//config DO6/7/9/10/11/12
			HAL_GPIO_WritePin(GPIOA, GPIO_PIN_15, GPIO_PIN_SET);
			HAL_GPIO_WritePin(GPIOE, GPIO_PIN_0|  GPIO_PIN_4|GPIO_PIN_5, GPIO_PIN_SET);
			HAL_GPIO_WritePin(GPIOE,  GPIO_PIN_1|GPIO_PIN_3, GPIO_PIN_RESET);

			if (xSemaphoreTake( uart_A1_xSemaphore,10000) == pdTRUE) {
					// hand shake
					// fill buffer as in tab3B1
					// function start: repeated code of hand shake sent tab3B1
					UART_send_buffer[0] = 0xA6;
					UART_send_buffer[1] = 0x0D;
					UART_send_buffer[2] = 0xAA;
					//https://zhidao.baidu.com/question/1638675882443131580.html?qbpn=2_2&tx=&word=%E4%BB%8E%E4%B8%80%E4%B8%AA16%E4%BD%8D%E5%8F%98%E9%87%8F%E4%B8%AD%E5%8F%96%E5%87%BA%E9%AB%988%E4%BD%8D%E5%92%8C%E4%BD%8E8%E4%BD%8D%EF%BC%8C%E6%B1%82C%E8%AF%AD%E8%A8%80%E7%A8%8B%E5%BA%8F%EF%BC%9F&fr=newsearchlist
					code_verify = (UART_recv_buffer[3] + UART_recv_buffer[4]) * UART_recv_buffer[5];
					UART_send_buffer[3] = code_verify & 0xff;
					UART_send_buffer[4] = (code_verify >> 8) & 0xff;
					UART_send_buffer[5] = (code_verify >> 16) & 0xff;
					UART_send_buffer[6] = (code_verify >> 24) & 0xff;
					UART_send_buffer[7] = 0x0B;
					UART_send_buffer[8] = 0x00;
					UART_send_buffer[9] = 0x00;
					UART_send_buffer[10] = 0x00;
					UART_send_buffer[11] = 0x00;
					frame_verify = UART_send_buffer[2] + UART_send_buffer[3] + UART_send_buffer[4] + UART_send_buffer[5] + \
											   UART_send_buffer[6] + UART_send_buffer[7] + UART_send_buffer[8] + UART_send_buffer[9] + \
												 UART_send_buffer[10];
					UART_send_buffer[12] = frame_verify & 0xff;
					UART_send_buffer[13] = 0x86;

					// send buffer
					HAL_UART_Transmit_DMA(&huart1, (uint8_t *)&UART_send_buffer, 13);   //choose uart line

					if (xSemaphoreTake( exti_xSemaphore, 10000) == pdTRUE) {
						time_origin = xTaskGetTickCount() * portTICK_RATE_MS;
						FieldHandle = osThreadNew(field_task, NULL, &field_attributes);
					}
					else {
						//error message
					}
			}

			return HAL_OK;

		case 0x07:
			if( FieldHandle != NULL ) {
				osThreadTerminate( FieldHandle );
			}
			HAL_TIM_PWM_Stop(&htim3, TIM_CHANNEL_1);
			__HAL_TIM_SET_AUTORELOAD(&htim3, 1500 - 1);
			__HAL_TIM_SET_COMPARE(&htim3, TIM_CHANNEL_1, 100 - 1);
			HAL_TIM_PWM_Start(&htim3, TIM_CHANNEL_1);
	//				pwm_count = 0;

		//config DO6/7/9/10/11/12
			HAL_GPIO_WritePin(GPIOA, GPIO_PIN_15, GPIO_PIN_SET);
			HAL_GPIO_WritePin(GPIOE, GPIO_PIN_0|  GPIO_PIN_4|GPIO_PIN_5, GPIO_PIN_SET);
			HAL_GPIO_WritePin(GPIOE,  GPIO_PIN_1|GPIO_PIN_3, GPIO_PIN_RESET);

			if (xSemaphoreTake( uart_A1_xSemaphore,10000) == pdTRUE) {
					// hand shake
					// fill buffer as in tab3B1
					// function start: repeated code of hand shake sent tab3B1
					UART_send_buffer[0] = 0xA6;
					UART_send_buffer[1] = 0x0D;
					UART_send_buffer[2] = 0xAA;
					//https://zhidao.baidu.com/question/1638675882443131580.html?qbpn=2_2&tx=&word=%E4%BB%8E%E4%B8%80%E4%B8%AA16%E4%BD%8D%E5%8F%98%E9%87%8F%E4%B8%AD%E5%8F%96%E5%87%BA%E9%AB%988%E4%BD%8D%E5%92%8C%E4%BD%8E8%E4%BD%8D%EF%BC%8C%E6%B1%82C%E8%AF%AD%E8%A8%80%E7%A8%8B%E5%BA%8F%EF%BC%9F&fr=newsearchlist
					code_verify = (UART_recv_buffer[3] + UART_recv_buffer[4]) * UART_recv_buffer[5];
					UART_send_buffer[3] = code_verify & 0xff;
					UART_send_buffer[4] = (code_verify >> 8) & 0xff;
					UART_send_buffer[5] = (code_verify >> 16) & 0xff;
					UART_send_buffer[6] = (code_verify >> 24) & 0xff;
					UART_send_buffer[7] = 0x0B;
					UART_send_buffer[8] = 0x00;
					UART_send_buffer[9] = 0x00;
					UART_send_buffer[10] = 0x00;
					UART_send_buffer[11] = 0x00;
					frame_verify = UART_send_buffer[2] + UART_send_buffer[3] + UART_send_buffer[4] + UART_send_buffer[5] + \
											   UART_send_buffer[6] + UART_send_buffer[7] + UART_send_buffer[8] + UART_send_buffer[9] + \
												 UART_send_buffer[10];
					UART_send_buffer[12] = frame_verify & 0xff;
					UART_send_buffer[13] = 0x86;

					// send buffer
					HAL_UART_Transmit_DMA(&huart1, (uint8_t *)&UART_send_buffer, 13);   //choose uart line

					if (xSemaphoreTake( exti_xSemaphore, 10000) == pdTRUE) {
						time_origin = xTaskGetTickCount() * portTICK_RATE_MS;
						FieldHandle = osThreadNew(field_task, NULL, &field_attributes);
					}
					else {
						//error message
					}
			}

			return HAL_OK;

		case 0x08:
			if( FieldHandle != NULL ) {
				osThreadTerminate( FieldHandle );
			}
			HAL_TIM_PWM_Stop(&htim3, TIM_CHANNEL_1);
			__HAL_TIM_SET_AUTORELOAD(&htim3, 1500 - 1);
			__HAL_TIM_SET_COMPARE(&htim3, TIM_CHANNEL_1, 100 - 1);
			HAL_TIM_PWM_Start(&htim3, TIM_CHANNEL_1);
	//				pwm_count = 0;

		//config DO6/7/9/10/11/12
			HAL_GPIO_WritePin(GPIOA, GPIO_PIN_15, GPIO_PIN_SET);
			HAL_GPIO_WritePin(GPIOE, GPIO_PIN_0|  GPIO_PIN_4|GPIO_PIN_5, GPIO_PIN_SET);
			HAL_GPIO_WritePin(GPIOE,  GPIO_PIN_1|GPIO_PIN_3, GPIO_PIN_RESET);

			if (xSemaphoreTake( uart_A1_xSemaphore,10000) == pdTRUE) {
					// hand shake
					// fill buffer as in tab3B1
					// function start: repeated code of hand shake sent tab3B1
					UART_send_buffer[0] = 0xA6;
					UART_send_buffer[1] = 0x0D;
					UART_send_buffer[2] = 0xAA;
					//https://zhidao.baidu.com/question/1638675882443131580.html?qbpn=2_2&tx=&word=%E4%BB%8E%E4%B8%80%E4%B8%AA16%E4%BD%8D%E5%8F%98%E9%87%8F%E4%B8%AD%E5%8F%96%E5%87%BA%E9%AB%988%E4%BD%8D%E5%92%8C%E4%BD%8E8%E4%BD%8D%EF%BC%8C%E6%B1%82C%E8%AF%AD%E8%A8%80%E7%A8%8B%E5%BA%8F%EF%BC%9F&fr=newsearchlist
					code_verify = (UART_recv_buffer[3] + UART_recv_buffer[4]) * UART_recv_buffer[5];
					UART_send_buffer[3] = code_verify & 0xff;
					UART_send_buffer[4] = (code_verify >> 8) & 0xff;
					UART_send_buffer[5] = (code_verify >> 16) & 0xff;
					UART_send_buffer[6] = (code_verify >> 24) & 0xff;
					UART_send_buffer[7] = 0x0B;
					UART_send_buffer[8] = 0x00;
					UART_send_buffer[9] = 0x00;
					UART_send_buffer[10] = 0x00;
					UART_send_buffer[11] = 0x00;
					frame_verify = UART_send_buffer[2] + UART_send_buffer[3] + UART_send_buffer[4] + UART_send_buffer[5] + \
											   UART_send_buffer[6] + UART_send_buffer[7] + UART_send_buffer[8] + UART_send_buffer[9] + \
												 UART_send_buffer[10];
					UART_send_buffer[12] = frame_verify & 0xff;
					UART_send_buffer[13] = 0x86;

					// send buffer
					HAL_UART_Transmit_DMA(&huart1, (uint8_t *)&UART_send_buffer, 13);   //choose uart line

					if (xSemaphoreTake( exti_xSemaphore, 10000) == pdTRUE) {
						time_origin = xTaskGetTickCount() * portTICK_RATE_MS;
						FieldHandle = osThreadNew(field_task, NULL, &field_attributes);
					}
					else {
						//error message
					}
			}

			return HAL_OK;

		case 0x09:
			if( FieldHandle != NULL ) {
				osThreadTerminate( FieldHandle );
			}
			HAL_TIM_PWM_Stop(&htim3, TIM_CHANNEL_1);
			__HAL_TIM_SET_AUTORELOAD(&htim3, 1500 - 1);
			__HAL_TIM_SET_COMPARE(&htim3, TIM_CHANNEL_1, 100 - 1);
			HAL_TIM_PWM_Start(&htim3, TIM_CHANNEL_1);
	//				pwm_count = 0;

		//config DO6/7/9/10/11/12
			HAL_GPIO_WritePin(GPIOA, GPIO_PIN_15, GPIO_PIN_SET);
			HAL_GPIO_WritePin(GPIOE, GPIO_PIN_0|  GPIO_PIN_4|GPIO_PIN_5, GPIO_PIN_SET);
			HAL_GPIO_WritePin(GPIOE,  GPIO_PIN_1|GPIO_PIN_3, GPIO_PIN_RESET);

			if (xSemaphoreTake( uart_A1_xSemaphore,10000) == pdTRUE) {
					// hand shake
					// fill buffer as in tab3B1
					// function start: repeated code of hand shake sent tab3B1
					UART_send_buffer[0] = 0xA6;
					UART_send_buffer[1] = 0x0D;
					UART_send_buffer[2] = 0xAA;
					//https://zhidao.baidu.com/question/1638675882443131580.html?qbpn=2_2&tx=&word=%E4%BB%8E%E4%B8%80%E4%B8%AA16%E4%BD%8D%E5%8F%98%E9%87%8F%E4%B8%AD%E5%8F%96%E5%87%BA%E9%AB%988%E4%BD%8D%E5%92%8C%E4%BD%8E8%E4%BD%8D%EF%BC%8C%E6%B1%82C%E8%AF%AD%E8%A8%80%E7%A8%8B%E5%BA%8F%EF%BC%9F&fr=newsearchlist
					code_verify = (UART_recv_buffer[3] + UART_recv_buffer[4]) * UART_recv_buffer[5];
					UART_send_buffer[3] = code_verify & 0xff;
					UART_send_buffer[4] = (code_verify >> 8) & 0xff;
					UART_send_buffer[5] = (code_verify >> 16) & 0xff;
					UART_send_buffer[6] = (code_verify >> 24) & 0xff;
					UART_send_buffer[7] = 0x0B;
					UART_send_buffer[8] = 0x00;
					UART_send_buffer[9] = 0x00;
					UART_send_buffer[10] = 0x00;
					UART_send_buffer[11] = 0x00;
					frame_verify = UART_send_buffer[2] + UART_send_buffer[3] + UART_send_buffer[4] + UART_send_buffer[5] + \
											   UART_send_buffer[6] + UART_send_buffer[7] + UART_send_buffer[8] + UART_send_buffer[9] + \
												 UART_send_buffer[10];
					UART_send_buffer[12] = frame_verify & 0xff;
					UART_send_buffer[13] = 0x86;

					// send buffer
					HAL_UART_Transmit_DMA(&huart1, (uint8_t *)&UART_send_buffer, 13);   //choose uart line

					if (xSemaphoreTake( exti_xSemaphore, 10000) == pdTRUE) {
						time_origin = xTaskGetTickCount() * portTICK_RATE_MS;
						FieldHandle = osThreadNew(field_task, NULL, &field_attributes);
					}
					else {
						//error message
					}
			}

			return HAL_OK;

		case 0x0A:
			if( FieldHandle != NULL ) {
				osThreadTerminate( FieldHandle );
			}
			HAL_TIM_PWM_Stop(&htim3, TIM_CHANNEL_1);
			__HAL_TIM_SET_AUTORELOAD(&htim3, 1400 - 1);
			__HAL_TIM_SET_COMPARE(&htim3, TIM_CHANNEL_1, 100 - 1);
			HAL_TIM_PWM_Start(&htim3, TIM_CHANNEL_1);
	//				pwm_count = 0;

		//config DO6/7/9/10/11/12
			HAL_GPIO_WritePin(GPIOA, GPIO_PIN_15, GPIO_PIN_SET);
			HAL_GPIO_WritePin(GPIOE, GPIO_PIN_0| GPIO_PIN_3 |GPIO_PIN_4|GPIO_PIN_5, GPIO_PIN_SET);
			HAL_GPIO_WritePin(GPIOE,  GPIO_PIN_1, GPIO_PIN_RESET);

			if (xSemaphoreTake( uart_A1_xSemaphore,10000) == pdTRUE) {
					// hand shake
					// fill buffer as in tab3B1
					// function start: repeated code of hand shake sent tab3B1
					UART_send_buffer[0] = 0xA6;
					UART_send_buffer[1] = 0x0D;
					UART_send_buffer[2] = 0xAA;
					//https://zhidao.baidu.com/question/1638675882443131580.html?qbpn=2_2&tx=&word=%E4%BB%8E%E4%B8%80%E4%B8%AA16%E4%BD%8D%E5%8F%98%E9%87%8F%E4%B8%AD%E5%8F%96%E5%87%BA%E9%AB%988%E4%BD%8D%E5%92%8C%E4%BD%8E8%E4%BD%8D%EF%BC%8C%E6%B1%82C%E8%AF%AD%E8%A8%80%E7%A8%8B%E5%BA%8F%EF%BC%9F&fr=newsearchlist
					code_verify = (UART_recv_buffer[3] + UART_recv_buffer[4]) * UART_recv_buffer[5];
					UART_send_buffer[3] = code_verify & 0xff;
					UART_send_buffer[4] = (code_verify >> 8) & 0xff;
					UART_send_buffer[5] = (code_verify >> 16) & 0xff;
					UART_send_buffer[6] = (code_verify >> 24) & 0xff;
					UART_send_buffer[7] = 0x0B;
					UART_send_buffer[8] = 0x00;
					UART_send_buffer[9] = 0x00;
					UART_send_buffer[10] = 0x00;
					UART_send_buffer[11] = 0x00;
					frame_verify = UART_send_buffer[2] + UART_send_buffer[3] + UART_send_buffer[4] + UART_send_buffer[5] + \
											   UART_send_buffer[6] + UART_send_buffer[7] + UART_send_buffer[8] + UART_send_buffer[9] + \
												 UART_send_buffer[10];
					UART_send_buffer[12] = frame_verify & 0xff;
					UART_send_buffer[13] = 0x86;

					// send buffer
					HAL_UART_Transmit_DMA(&huart1, (uint8_t *)&UART_send_buffer, 13);   //choose uart line

					if (xSemaphoreTake( exti_xSemaphore, 10000) == pdTRUE) {
						time_origin = xTaskGetTickCount() * portTICK_RATE_MS;
						FieldHandle = osThreadNew(field_task, NULL, &field_attributes);
					}
					else {
						//error message
					}
			}

			return HAL_OK;

		case 0x0B:
			if( FieldHandle != NULL ) {
				osThreadTerminate( FieldHandle );
			}
			HAL_TIM_PWM_Stop(&htim3, TIM_CHANNEL_1);
			__HAL_TIM_SET_AUTORELOAD(&htim3, 1400 - 1);
			__HAL_TIM_SET_COMPARE(&htim3, TIM_CHANNEL_1, 100 - 1);
			HAL_TIM_PWM_Start(&htim3, TIM_CHANNEL_1);
	//				pwm_count = 0;

		//config DO6/7/9/10/11/12
			HAL_GPIO_WritePin(GPIOA, GPIO_PIN_15, GPIO_PIN_SET);
			HAL_GPIO_WritePin(GPIOE, GPIO_PIN_0| GPIO_PIN_3 |GPIO_PIN_4|GPIO_PIN_5, GPIO_PIN_SET);
			HAL_GPIO_WritePin(GPIOE,  GPIO_PIN_1, GPIO_PIN_RESET);

			if (xSemaphoreTake( uart_A1_xSemaphore,10000) == pdTRUE) {
					// hand shake
					// fill buffer as in tab3B1
					// function start: repeated code of hand shake sent tab3B1
					UART_send_buffer[0] = 0xA6;
					UART_send_buffer[1] = 0x0D;
					UART_send_buffer[2] = 0xAA;
					//https://zhidao.baidu.com/question/1638675882443131580.html?qbpn=2_2&tx=&word=%E4%BB%8E%E4%B8%80%E4%B8%AA16%E4%BD%8D%E5%8F%98%E9%87%8F%E4%B8%AD%E5%8F%96%E5%87%BA%E9%AB%988%E4%BD%8D%E5%92%8C%E4%BD%8E8%E4%BD%8D%EF%BC%8C%E6%B1%82C%E8%AF%AD%E8%A8%80%E7%A8%8B%E5%BA%8F%EF%BC%9F&fr=newsearchlist
					code_verify = (UART_recv_buffer[3] + UART_recv_buffer[4]) * UART_recv_buffer[5];
					UART_send_buffer[3] = code_verify & 0xff;
					UART_send_buffer[4] = (code_verify >> 8) & 0xff;
					UART_send_buffer[5] = (code_verify >> 16) & 0xff;
					UART_send_buffer[6] = (code_verify >> 24) & 0xff;
					UART_send_buffer[7] = 0x0B;
					UART_send_buffer[8] = 0x00;
					UART_send_buffer[9] = 0x00;
					UART_send_buffer[10] = 0x00;
					UART_send_buffer[11] = 0x00;
					frame_verify = UART_send_buffer[2] + UART_send_buffer[3] + UART_send_buffer[4] + UART_send_buffer[5] + \
											   UART_send_buffer[6] + UART_send_buffer[7] + UART_send_buffer[8] + UART_send_buffer[9] + \
												 UART_send_buffer[10];
					UART_send_buffer[12] = frame_verify & 0xff;
					UART_send_buffer[13] = 0x86;

					// send buffer
					HAL_UART_Transmit_DMA(&huart1, (uint8_t *)&UART_send_buffer, 13);   //choose uart line

					if (xSemaphoreTake( exti_xSemaphore, 10000) == pdTRUE) {
						time_origin = xTaskGetTickCount() * portTICK_RATE_MS;
						FieldHandle = osThreadNew(field_task, NULL, &field_attributes);
					}
					else {
						//error message
					}
			}

			return HAL_OK;

		case 0x0C:
			if( FieldHandle != NULL ) {
				osThreadTerminate( FieldHandle );
			}
			HAL_TIM_PWM_Stop(&htim3, TIM_CHANNEL_1);
			__HAL_TIM_SET_AUTORELOAD(&htim3, 1400 - 1);
			__HAL_TIM_SET_COMPARE(&htim3, TIM_CHANNEL_1, 100 - 1);
			HAL_TIM_PWM_Start(&htim3, TIM_CHANNEL_1);
	//				pwm_count = 0;

		//config DO6/7/9/10/11/12
			HAL_GPIO_WritePin(GPIOA, GPIO_PIN_15, GPIO_PIN_SET);
			HAL_GPIO_WritePin(GPIOE, GPIO_PIN_0| GPIO_PIN_3 |GPIO_PIN_4|GPIO_PIN_5, GPIO_PIN_SET);
			HAL_GPIO_WritePin(GPIOE,  GPIO_PIN_1, GPIO_PIN_RESET);

			if (xSemaphoreTake( uart_A1_xSemaphore,10000) == pdTRUE) {
					// hand shake
					// fill buffer as in tab3B1
					// function start: repeated code of hand shake sent tab3B1
					UART_send_buffer[0] = 0xA6;
					UART_send_buffer[1] = 0x0D;
					UART_send_buffer[2] = 0xAA;
					//https://zhidao.baidu.com/question/1638675882443131580.html?qbpn=2_2&tx=&word=%E4%BB%8E%E4%B8%80%E4%B8%AA16%E4%BD%8D%E5%8F%98%E9%87%8F%E4%B8%AD%E5%8F%96%E5%87%BA%E9%AB%988%E4%BD%8D%E5%92%8C%E4%BD%8E8%E4%BD%8D%EF%BC%8C%E6%B1%82C%E8%AF%AD%E8%A8%80%E7%A8%8B%E5%BA%8F%EF%BC%9F&fr=newsearchlist
					code_verify = (UART_recv_buffer[3] + UART_recv_buffer[4]) * UART_recv_buffer[5];
					UART_send_buffer[3] = code_verify & 0xff;
					UART_send_buffer[4] = (code_verify >> 8) & 0xff;
					UART_send_buffer[5] = (code_verify >> 16) & 0xff;
					UART_send_buffer[6] = (code_verify >> 24) & 0xff;
					UART_send_buffer[7] = 0x0B;
					UART_send_buffer[8] = 0x00;
					UART_send_buffer[9] = 0x00;
					UART_send_buffer[10] = 0x00;
					UART_send_buffer[11] = 0x00;
					frame_verify = UART_send_buffer[2] + UART_send_buffer[3] + UART_send_buffer[4] + UART_send_buffer[5] + \
											   UART_send_buffer[6] + UART_send_buffer[7] + UART_send_buffer[8] + UART_send_buffer[9] + \
												 UART_send_buffer[10];
					UART_send_buffer[12] = frame_verify & 0xff;
					UART_send_buffer[13] = 0x86;

					// send buffer
					HAL_UART_Transmit_DMA(&huart1, (uint8_t *)&UART_send_buffer, 13);   //choose uart line

					if (xSemaphoreTake( exti_xSemaphore, 10000) == pdTRUE) {
						time_origin = xTaskGetTickCount() * portTICK_RATE_MS;
						FieldHandle = osThreadNew(field_task, NULL, &field_attributes);
					}
					else {
						//error message
					}
			}

			return HAL_OK;

		case 0x0D:
			if( FieldHandle != NULL ) {
				osThreadTerminate( FieldHandle );
			}
			HAL_TIM_PWM_Stop(&htim3, TIM_CHANNEL_1);
			__HAL_TIM_SET_AUTORELOAD(&htim3, 1400 - 1);
			__HAL_TIM_SET_COMPARE(&htim3, TIM_CHANNEL_1, 100 - 1);
			HAL_TIM_PWM_Start(&htim3, TIM_CHANNEL_1);
	//				pwm_count = 0;

		//config DO6/7/9/10/11/12
			HAL_GPIO_WritePin(GPIOA, GPIO_PIN_15, GPIO_PIN_SET);
			HAL_GPIO_WritePin(GPIOE, GPIO_PIN_0| GPIO_PIN_3 |GPIO_PIN_4|GPIO_PIN_5, GPIO_PIN_SET);
			HAL_GPIO_WritePin(GPIOE,  GPIO_PIN_1, GPIO_PIN_RESET);

			if (xSemaphoreTake( uart_A1_xSemaphore,10000) == pdTRUE) {
					// hand shake
					// fill buffer as in tab3B1
					// function start: repeated code of hand shake sent tab3B1
					UART_send_buffer[0] = 0xA6;
					UART_send_buffer[1] = 0x0D;
					UART_send_buffer[2] = 0xAA;
					//https://zhidao.baidu.com/question/1638675882443131580.html?qbpn=2_2&tx=&word=%E4%BB%8E%E4%B8%80%E4%B8%AA16%E4%BD%8D%E5%8F%98%E9%87%8F%E4%B8%AD%E5%8F%96%E5%87%BA%E9%AB%988%E4%BD%8D%E5%92%8C%E4%BD%8E8%E4%BD%8D%EF%BC%8C%E6%B1%82C%E8%AF%AD%E8%A8%80%E7%A8%8B%E5%BA%8F%EF%BC%9F&fr=newsearchlist
					code_verify = (UART_recv_buffer[3] + UART_recv_buffer[4]) * UART_recv_buffer[5];
					UART_send_buffer[3] = code_verify & 0xff;
					UART_send_buffer[4] = (code_verify >> 8) & 0xff;
					UART_send_buffer[5] = (code_verify >> 16) & 0xff;
					UART_send_buffer[6] = (code_verify >> 24) & 0xff;
					UART_send_buffer[7] = 0x0B;
					UART_send_buffer[8] = 0x00;
					UART_send_buffer[9] = 0x00;
					UART_send_buffer[10] = 0x00;
					UART_send_buffer[11] = 0x00;
					frame_verify = UART_send_buffer[2] + UART_send_buffer[3] + UART_send_buffer[4] + UART_send_buffer[5] + \
											   UART_send_buffer[6] + UART_send_buffer[7] + UART_send_buffer[8] + UART_send_buffer[9] + \
												 UART_send_buffer[10];
					UART_send_buffer[12] = frame_verify & 0xff;
					UART_send_buffer[13] = 0x86;

					// send buffer
					HAL_UART_Transmit_DMA(&huart1, (uint8_t *)&UART_send_buffer, 13);   //choose uart line

					if (xSemaphoreTake( exti_xSemaphore, 10000) == pdTRUE) {
						time_origin = xTaskGetTickCount() * portTICK_RATE_MS;
						FieldHandle = osThreadNew(field_task, NULL, &field_attributes);
					}
					else {
						//error message
					}
			}

			return HAL_OK;

		case 0x0E:
			if( FieldHandle != NULL ) {
				osThreadTerminate( FieldHandle );
			}
			HAL_TIM_PWM_Stop(&htim3, TIM_CHANNEL_1);
			__HAL_TIM_SET_AUTORELOAD(&htim3, 1000 - 1);
			__HAL_TIM_SET_COMPARE(&htim3, TIM_CHANNEL_1, 100 - 1);
			HAL_TIM_PWM_Start(&htim3, TIM_CHANNEL_1);
	//				pwm_count = 0;

		//config DO6/7/9/10/11/12
			HAL_GPIO_WritePin(GPIOA, GPIO_PIN_15, GPIO_PIN_SET);
			HAL_GPIO_WritePin(GPIOE, GPIO_PIN_0 |GPIO_PIN_4|GPIO_PIN_5, GPIO_PIN_SET);
			HAL_GPIO_WritePin(GPIOE,  GPIO_PIN_1| GPIO_PIN_3, GPIO_PIN_RESET);

			if (xSemaphoreTake( uart_A1_xSemaphore,10000) == pdTRUE) {
					// hand shake
					// fill buffer as in tab3B1
					// function start: repeated code of hand shake sent tab3B1
					UART_send_buffer[0] = 0xA6;
					UART_send_buffer[1] = 0x0D;
					UART_send_buffer[2] = 0xAA;
					//https://zhidao.baidu.com/question/1638675882443131580.html?qbpn=2_2&tx=&word=%E4%BB%8E%E4%B8%80%E4%B8%AA16%E4%BD%8D%E5%8F%98%E9%87%8F%E4%B8%AD%E5%8F%96%E5%87%BA%E9%AB%988%E4%BD%8D%E5%92%8C%E4%BD%8E8%E4%BD%8D%EF%BC%8C%E6%B1%82C%E8%AF%AD%E8%A8%80%E7%A8%8B%E5%BA%8F%EF%BC%9F&fr=newsearchlist
					code_verify = (UART_recv_buffer[3] + UART_recv_buffer[4]) * UART_recv_buffer[5];
					UART_send_buffer[3] = code_verify & 0xff;
					UART_send_buffer[4] = (code_verify >> 8) & 0xff;
					UART_send_buffer[5] = (code_verify >> 16) & 0xff;
					UART_send_buffer[6] = (code_verify >> 24) & 0xff;
					UART_send_buffer[7] = 0x0B;
					UART_send_buffer[8] = 0x00;
					UART_send_buffer[9] = 0x00;
					UART_send_buffer[10] = 0x00;
					UART_send_buffer[11] = 0x00;
					frame_verify = UART_send_buffer[2] + UART_send_buffer[3] + UART_send_buffer[4] + UART_send_buffer[5] + \
											   UART_send_buffer[6] + UART_send_buffer[7] + UART_send_buffer[8] + UART_send_buffer[9] + \
												 UART_send_buffer[10];
					UART_send_buffer[12] = frame_verify & 0xff;
					UART_send_buffer[13] = 0x86;

					// send buffer
					HAL_UART_Transmit_DMA(&huart1, (uint8_t *)&UART_send_buffer, 13);   //choose uart line

					if (xSemaphoreTake( exti_xSemaphore, 10000) == pdTRUE) {
						time_origin = xTaskGetTickCount() * portTICK_RATE_MS;
						FieldHandle = osThreadNew(field_task, NULL, &field_attributes);
					}
					else {
						//error message
					}
			}

			return HAL_OK;

		case 0x0F:
			if( FieldHandle != NULL ) {
				osThreadTerminate( FieldHandle );
			}
			HAL_TIM_PWM_Stop(&htim3, TIM_CHANNEL_1);
			__HAL_TIM_SET_AUTORELOAD(&htim3, 2000 - 1);
			__HAL_TIM_SET_COMPARE(&htim3, TIM_CHANNEL_1, 100 - 1);
			HAL_TIM_PWM_Start(&htim3, TIM_CHANNEL_1);
	//				pwm_count = 0;

		//config DO6/7/9/10/11/12
			HAL_GPIO_WritePin(GPIOA, GPIO_PIN_15, GPIO_PIN_SET);
			HAL_GPIO_WritePin(GPIOE, GPIO_PIN_0 |GPIO_PIN_4|GPIO_PIN_5, GPIO_PIN_SET);
			HAL_GPIO_WritePin(GPIOE,  GPIO_PIN_1| GPIO_PIN_3, GPIO_PIN_RESET);

			if (xSemaphoreTake( uart_A1_xSemaphore,10000) == pdTRUE) {
					// hand shake
					// fill buffer as in tab3B1
					// function start: repeated code of hand shake sent tab3B1
					UART_send_buffer[0] = 0xA6;
					UART_send_buffer[1] = 0x0D;
					UART_send_buffer[2] = 0xAA;
					//https://zhidao.baidu.com/question/1638675882443131580.html?qbpn=2_2&tx=&word=%E4%BB%8E%E4%B8%80%E4%B8%AA16%E4%BD%8D%E5%8F%98%E9%87%8F%E4%B8%AD%E5%8F%96%E5%87%BA%E9%AB%988%E4%BD%8D%E5%92%8C%E4%BD%8E8%E4%BD%8D%EF%BC%8C%E6%B1%82C%E8%AF%AD%E8%A8%80%E7%A8%8B%E5%BA%8F%EF%BC%9F&fr=newsearchlist
					code_verify = (UART_recv_buffer[3] + UART_recv_buffer[4]) * UART_recv_buffer[5];
					UART_send_buffer[3] = code_verify & 0xff;
					UART_send_buffer[4] = (code_verify >> 8) & 0xff;
					UART_send_buffer[5] = (code_verify >> 16) & 0xff;
					UART_send_buffer[6] = (code_verify >> 24) & 0xff;
					UART_send_buffer[7] = 0x0B;
					UART_send_buffer[8] = 0x00;
					UART_send_buffer[9] = 0x00;
					UART_send_buffer[10] = 0x00;
					UART_send_buffer[11] = 0x00;
					frame_verify = UART_send_buffer[2] + UART_send_buffer[3] + UART_send_buffer[4] + UART_send_buffer[5] + \
											   UART_send_buffer[6] + UART_send_buffer[7] + UART_send_buffer[8] + UART_send_buffer[9] + \
												 UART_send_buffer[10];
					UART_send_buffer[12] = frame_verify & 0xff;
					UART_send_buffer[13] = 0x86;

					// send buffer
					HAL_UART_Transmit_DMA(&huart1, (uint8_t *)&UART_send_buffer, 13);   //choose uart line

					if (xSemaphoreTake( exti_xSemaphore, 10000) == pdTRUE) {
						time_origin = xTaskGetTickCount() * portTICK_RATE_MS;
						FieldHandle = osThreadNew(field_task, NULL, &field_attributes);
					}
					else {
						//error message
					}
			}

			return HAL_OK;

		case 0x10:
			if( FieldHandle != NULL ) {
				osThreadTerminate( FieldHandle );
			}
			HAL_TIM_PWM_Stop(&htim3, TIM_CHANNEL_1);
			__HAL_TIM_SET_AUTORELOAD(&htim3, 1000 - 1);
			__HAL_TIM_SET_COMPARE(&htim3, TIM_CHANNEL_1, 100 - 1);
			HAL_TIM_PWM_Start(&htim3, TIM_CHANNEL_1);
	//				pwm_count = 0;

		//config DO6/7/9/10/11/12
			HAL_GPIO_WritePin(GPIOA, GPIO_PIN_15, GPIO_PIN_SET);
			HAL_GPIO_WritePin(GPIOE, GPIO_PIN_0| GPIO_PIN_3 |GPIO_PIN_4|GPIO_PIN_5, GPIO_PIN_SET);
			HAL_GPIO_WritePin(GPIOE,  GPIO_PIN_1, GPIO_PIN_RESET);

			if (xSemaphoreTake( uart_A1_xSemaphore,10000) == pdTRUE) {
					// hand shake
					// fill buffer as in tab3B1
					// function start: repeated code of hand shake sent tab3B1
					UART_send_buffer[0] = 0xA6;
					UART_send_buffer[1] = 0x0D;
					UART_send_buffer[2] = 0xAA;
					//https://zhidao.baidu.com/question/1638675882443131580.html?qbpn=2_2&tx=&word=%E4%BB%8E%E4%B8%80%E4%B8%AA16%E4%BD%8D%E5%8F%98%E9%87%8F%E4%B8%AD%E5%8F%96%E5%87%BA%E9%AB%988%E4%BD%8D%E5%92%8C%E4%BD%8E8%E4%BD%8D%EF%BC%8C%E6%B1%82C%E8%AF%AD%E8%A8%80%E7%A8%8B%E5%BA%8F%EF%BC%9F&fr=newsearchlist
					code_verify = (UART_recv_buffer[3] + UART_recv_buffer[4]) * UART_recv_buffer[5];
					UART_send_buffer[3] = code_verify & 0xff;
					UART_send_buffer[4] = (code_verify >> 8) & 0xff;
					UART_send_buffer[5] = (code_verify >> 16) & 0xff;
					UART_send_buffer[6] = (code_verify >> 24) & 0xff;
					UART_send_buffer[7] = 0x0B;
					UART_send_buffer[8] = 0x00;
					UART_send_buffer[9] = 0x00;
					UART_send_buffer[10] = 0x00;
					UART_send_buffer[11] = 0x00;
					frame_verify = UART_send_buffer[2] + UART_send_buffer[3] + UART_send_buffer[4] + UART_send_buffer[5] + \
											   UART_send_buffer[6] + UART_send_buffer[7] + UART_send_buffer[8] + UART_send_buffer[9] + \
												 UART_send_buffer[10];
					UART_send_buffer[12] = frame_verify & 0xff;
					UART_send_buffer[13] = 0x86;

					// send buffer
					HAL_UART_Transmit_DMA(&huart1, (uint8_t *)&UART_send_buffer, 13);   //choose uart line

					if (xSemaphoreTake( exti_xSemaphore, 10000) == pdTRUE) {
						time_origin = xTaskGetTickCount() * portTICK_RATE_MS;
						FieldHandle = osThreadNew(field_task, NULL, &field_attributes);
					}
					else {
						//error message
					}
			}

			return HAL_OK;

		case 0x11:
			if( FieldHandle != NULL ) {
				osThreadTerminate( FieldHandle );
			}
			HAL_TIM_PWM_Stop(&htim3, TIM_CHANNEL_1);
			__HAL_TIM_SET_AUTORELOAD(&htim3, 2000 - 1);
			__HAL_TIM_SET_COMPARE(&htim3, TIM_CHANNEL_1, 100 - 1);
			HAL_TIM_PWM_Start(&htim3, TIM_CHANNEL_1);
	//				pwm_count = 0;

		//config DO6/7/9/10/11/12
			HAL_GPIO_WritePin(GPIOA, GPIO_PIN_15, GPIO_PIN_SET);
			HAL_GPIO_WritePin(GPIOE, GPIO_PIN_0| GPIO_PIN_3 |GPIO_PIN_4|GPIO_PIN_5, GPIO_PIN_SET);
			HAL_GPIO_WritePin(GPIOE,  GPIO_PIN_1, GPIO_PIN_RESET);

			if (xSemaphoreTake( uart_A1_xSemaphore,10000) == pdTRUE) {
					// hand shake
					// fill buffer as in tab3B1
					// function start: repeated code of hand shake sent tab3B1
					UART_send_buffer[0] = 0xA6;
					UART_send_buffer[1] = 0x0D;
					UART_send_buffer[2] = 0xAA;
					//https://zhidao.baidu.com/question/1638675882443131580.html?qbpn=2_2&tx=&word=%E4%BB%8E%E4%B8%80%E4%B8%AA16%E4%BD%8D%E5%8F%98%E9%87%8F%E4%B8%AD%E5%8F%96%E5%87%BA%E9%AB%988%E4%BD%8D%E5%92%8C%E4%BD%8E8%E4%BD%8D%EF%BC%8C%E6%B1%82C%E8%AF%AD%E8%A8%80%E7%A8%8B%E5%BA%8F%EF%BC%9F&fr=newsearchlist
					code_verify = (UART_recv_buffer[3] + UART_recv_buffer[4]) * UART_recv_buffer[5];
					UART_send_buffer[3] = code_verify & 0xff;
					UART_send_buffer[4] = (code_verify >> 8) & 0xff;
					UART_send_buffer[5] = (code_verify >> 16) & 0xff;
					UART_send_buffer[6] = (code_verify >> 24) & 0xff;
					UART_send_buffer[7] = 0x0B;
					UART_send_buffer[8] = 0x00;
					UART_send_buffer[9] = 0x00;
					UART_send_buffer[10] = 0x00;
					UART_send_buffer[11] = 0x00;
					frame_verify = UART_send_buffer[2] + UART_send_buffer[3] + UART_send_buffer[4] + UART_send_buffer[5] + \
											   UART_send_buffer[6] + UART_send_buffer[7] + UART_send_buffer[8] + UART_send_buffer[9] + \
												 UART_send_buffer[10];
					UART_send_buffer[12] = frame_verify & 0xff;
					UART_send_buffer[13] = 0x86;

					// send buffer
					HAL_UART_Transmit_DMA(&huart1, (uint8_t *)&UART_send_buffer, 13);   //choose uart line

					if (xSemaphoreTake( exti_xSemaphore, 10000) == pdTRUE) {
						time_origin = xTaskGetTickCount() * portTICK_RATE_MS;
						FieldHandle = osThreadNew(field_task, NULL, &field_attributes);
					}
					else {
						//error message
					}
			}

			return HAL_OK;

		case 0x12:
			if( FieldHandle != NULL ) {
				osThreadTerminate( FieldHandle );
			}
			HAL_TIM_PWM_Stop(&htim3, TIM_CHANNEL_1);
			__HAL_TIM_SET_AUTORELOAD(&htim3, 1333- 1);
			__HAL_TIM_SET_COMPARE(&htim3, TIM_CHANNEL_1, 100 - 1);
			HAL_TIM_PWM_Start(&htim3, TIM_CHANNEL_1);
	//				pwm_count = 0;

		//config DO6/7/9/10/11/12
			HAL_GPIO_WritePin(GPIOA, GPIO_PIN_15, GPIO_PIN_SET);
			HAL_GPIO_WritePin(GPIOE, GPIO_PIN_0 |GPIO_PIN_4|GPIO_PIN_5, GPIO_PIN_SET);
			HAL_GPIO_WritePin(GPIOE,  GPIO_PIN_1| GPIO_PIN_3, GPIO_PIN_RESET);

			if (xSemaphoreTake( uart_A1_xSemaphore,10000) == pdTRUE) {
					// hand shake
					// fill buffer as in tab3B1
					// function start: repeated code of hand shake sent tab3B1
					UART_send_buffer[0] = 0xA6;
					UART_send_buffer[1] = 0x0D;
					UART_send_buffer[2] = 0xAA;
					//https://zhidao.baidu.com/question/1638675882443131580.html?qbpn=2_2&tx=&word=%E4%BB%8E%E4%B8%80%E4%B8%AA16%E4%BD%8D%E5%8F%98%E9%87%8F%E4%B8%AD%E5%8F%96%E5%87%BA%E9%AB%988%E4%BD%8D%E5%92%8C%E4%BD%8E8%E4%BD%8D%EF%BC%8C%E6%B1%82C%E8%AF%AD%E8%A8%80%E7%A8%8B%E5%BA%8F%EF%BC%9F&fr=newsearchlist
					code_verify = (UART_recv_buffer[3] + UART_recv_buffer[4]) * UART_recv_buffer[5];
					UART_send_buffer[3] = code_verify & 0xff;
					UART_send_buffer[4] = (code_verify >> 8) & 0xff;
					UART_send_buffer[5] = (code_verify >> 16) & 0xff;
					UART_send_buffer[6] = (code_verify >> 24) & 0xff;
					UART_send_buffer[7] = 0x0B;
					UART_send_buffer[8] = 0x00;
					UART_send_buffer[9] = 0x00;
					UART_send_buffer[10] = 0x00;
					UART_send_buffer[11] = 0x00;
					frame_verify = UART_send_buffer[2] + UART_send_buffer[3] + UART_send_buffer[4] + UART_send_buffer[5] + \
											   UART_send_buffer[6] + UART_send_buffer[7] + UART_send_buffer[8] + UART_send_buffer[9] + \
												 UART_send_buffer[10];
					UART_send_buffer[12] = frame_verify & 0xff;
					UART_send_buffer[13] = 0x86;

					// send buffer
					HAL_UART_Transmit_DMA(&huart1, (uint8_t *)&UART_send_buffer, 13);   //choose uart line

					if (xSemaphoreTake( exti_xSemaphore, 10000) == pdTRUE) {
						time_origin = xTaskGetTickCount() * portTICK_RATE_MS;
						FieldHandle = osThreadNew(field_task, NULL, &field_attributes);
					}
					else {
						//error message
					}
			}

			return HAL_OK;

		case 0x13:
			if( FieldHandle != NULL ) {
				osThreadTerminate( FieldHandle );
			}
			HAL_TIM_PWM_Stop(&htim3, TIM_CHANNEL_1);
			__HAL_TIM_SET_AUTORELOAD(&htim3, 1333 - 1);
			__HAL_TIM_SET_COMPARE(&htim3, TIM_CHANNEL_1, 100 - 1);
			HAL_TIM_PWM_Start(&htim3, TIM_CHANNEL_1);
	//				pwm_count = 0;

		//config DO6/7/9/10/11/12
			HAL_GPIO_WritePin(GPIOA, GPIO_PIN_15, GPIO_PIN_SET);
			HAL_GPIO_WritePin(GPIOE, GPIO_PIN_0 |GPIO_PIN_4|GPIO_PIN_5, GPIO_PIN_SET);
			HAL_GPIO_WritePin(GPIOE,  GPIO_PIN_1| GPIO_PIN_3, GPIO_PIN_RESET);

			if (xSemaphoreTake( uart_A1_xSemaphore,10000) == pdTRUE) {
					// hand shake
					// fill buffer as in tab3B1
					// function start: repeated code of hand shake sent tab3B1
					UART_send_buffer[0] = 0xA6;
					UART_send_buffer[1] = 0x0D;
					UART_send_buffer[2] = 0xAA;
					//https://zhidao.baidu.com/question/1638675882443131580.html?qbpn=2_2&tx=&word=%E4%BB%8E%E4%B8%80%E4%B8%AA16%E4%BD%8D%E5%8F%98%E9%87%8F%E4%B8%AD%E5%8F%96%E5%87%BA%E9%AB%988%E4%BD%8D%E5%92%8C%E4%BD%8E8%E4%BD%8D%EF%BC%8C%E6%B1%82C%E8%AF%AD%E8%A8%80%E7%A8%8B%E5%BA%8F%EF%BC%9F&fr=newsearchlist
					code_verify = (UART_recv_buffer[3] + UART_recv_buffer[4]) * UART_recv_buffer[5];
					UART_send_buffer[3] = code_verify & 0xff;
					UART_send_buffer[4] = (code_verify >> 8) & 0xff;
					UART_send_buffer[5] = (code_verify >> 16) & 0xff;
					UART_send_buffer[6] = (code_verify >> 24) & 0xff;
					UART_send_buffer[7] = 0x0B;
					UART_send_buffer[8] = 0x00;
					UART_send_buffer[9] = 0x00;
					UART_send_buffer[10] = 0x00;
					UART_send_buffer[11] = 0x00;
					frame_verify = UART_send_buffer[2] + UART_send_buffer[3] + UART_send_buffer[4] + UART_send_buffer[5] + \
											   UART_send_buffer[6] + UART_send_buffer[7] + UART_send_buffer[8] + UART_send_buffer[9] + \
												 UART_send_buffer[10];
					UART_send_buffer[12] = frame_verify & 0xff;
					UART_send_buffer[13] = 0x86;

					// send buffer
					HAL_UART_Transmit_DMA(&huart1, (uint8_t *)&UART_send_buffer, 13);   //choose uart line

					if (xSemaphoreTake( exti_xSemaphore, 10000) == pdTRUE) {
						time_origin = xTaskGetTickCount() * portTICK_RATE_MS;
						FieldHandle = osThreadNew(field_task, NULL, &field_attributes);
					}
					else {
						//error message
					}
			}

			return HAL_OK;

		case 0x14:
			if( FieldHandle != NULL ) {
				osThreadTerminate( FieldHandle );
			}
			HAL_TIM_PWM_Stop(&htim3, TIM_CHANNEL_1);
			__HAL_TIM_SET_AUTORELOAD(&htim3, 1333 - 1);
			__HAL_TIM_SET_COMPARE(&htim3, TIM_CHANNEL_1, 100 - 1);
			HAL_TIM_PWM_Start(&htim3, TIM_CHANNEL_1);
	//				pwm_count = 0;

		//config DO6/7/9/10/11/12
			HAL_GPIO_WritePin(GPIOA, GPIO_PIN_15, GPIO_PIN_SET);
			HAL_GPIO_WritePin(GPIOE, GPIO_PIN_0 |GPIO_PIN_4|GPIO_PIN_5, GPIO_PIN_SET);
			HAL_GPIO_WritePin(GPIOE,  GPIO_PIN_1| GPIO_PIN_3, GPIO_PIN_RESET);

			if (xSemaphoreTake( uart_A1_xSemaphore,10000) == pdTRUE) {
					// hand shake
					// fill buffer as in tab3B1
					// function start: repeated code of hand shake sent tab3B1
					UART_send_buffer[0] = 0xA6;
					UART_send_buffer[1] = 0x0D;
					UART_send_buffer[2] = 0xAA;
					//https://zhidao.baidu.com/question/1638675882443131580.html?qbpn=2_2&tx=&word=%E4%BB%8E%E4%B8%80%E4%B8%AA16%E4%BD%8D%E5%8F%98%E9%87%8F%E4%B8%AD%E5%8F%96%E5%87%BA%E9%AB%988%E4%BD%8D%E5%92%8C%E4%BD%8E8%E4%BD%8D%EF%BC%8C%E6%B1%82C%E8%AF%AD%E8%A8%80%E7%A8%8B%E5%BA%8F%EF%BC%9F&fr=newsearchlist
					code_verify = (UART_recv_buffer[3] + UART_recv_buffer[4]) * UART_recv_buffer[5];
					UART_send_buffer[3] = code_verify & 0xff;
					UART_send_buffer[4] = (code_verify >> 8) & 0xff;
					UART_send_buffer[5] = (code_verify >> 16) & 0xff;
					UART_send_buffer[6] = (code_verify >> 24) & 0xff;
					UART_send_buffer[7] = 0x0B;
					UART_send_buffer[8] = 0x00;
					UART_send_buffer[9] = 0x00;
					UART_send_buffer[10] = 0x00;
					UART_send_buffer[11] = 0x00;
					frame_verify = UART_send_buffer[2] + UART_send_buffer[3] + UART_send_buffer[4] + UART_send_buffer[5] + \
											   UART_send_buffer[6] + UART_send_buffer[7] + UART_send_buffer[8] + UART_send_buffer[9] + \
												 UART_send_buffer[10];
					UART_send_buffer[12] = frame_verify & 0xff;
					UART_send_buffer[13] = 0x86;

					// send buffer
					HAL_UART_Transmit_DMA(&huart1, (uint8_t *)&UART_send_buffer, 13);   //choose uart line

					if (xSemaphoreTake( exti_xSemaphore, 10000) == pdTRUE) {
						time_origin = xTaskGetTickCount() * portTICK_RATE_MS;
						FieldHandle = osThreadNew(field_task, NULL, &field_attributes);
					}
					else {
						//error message
					}
			}

			return HAL_OK;

		case 0x15:
			if( FieldHandle != NULL ) {
				osThreadTerminate( FieldHandle );
			}
			HAL_TIM_PWM_Stop(&htim3, TIM_CHANNEL_1);
			__HAL_TIM_SET_AUTORELOAD(&htim3, 1333 - 1);
			__HAL_TIM_SET_COMPARE(&htim3, TIM_CHANNEL_1, 100 - 1);
			HAL_TIM_PWM_Start(&htim3, TIM_CHANNEL_1);
	//				pwm_count = 0;

		//config DO6/7/9/10/11/12
			HAL_GPIO_WritePin(GPIOA, GPIO_PIN_15, GPIO_PIN_SET);
			HAL_GPIO_WritePin(GPIOE, GPIO_PIN_0 |GPIO_PIN_4|GPIO_PIN_5, GPIO_PIN_SET);
			HAL_GPIO_WritePin(GPIOE,  GPIO_PIN_1| GPIO_PIN_3, GPIO_PIN_RESET);

			if (xSemaphoreTake( uart_A1_xSemaphore,10000) == pdTRUE) {
					// hand shake
					// fill buffer as in tab3B1
					// function start: repeated code of hand shake sent tab3B1
					UART_send_buffer[0] = 0xA6;
					UART_send_buffer[1] = 0x0D;
					UART_send_buffer[2] = 0xAA;
					//https://zhidao.baidu.com/question/1638675882443131580.html?qbpn=2_2&tx=&word=%E4%BB%8E%E4%B8%80%E4%B8%AA16%E4%BD%8D%E5%8F%98%E9%87%8F%E4%B8%AD%E5%8F%96%E5%87%BA%E9%AB%988%E4%BD%8D%E5%92%8C%E4%BD%8E8%E4%BD%8D%EF%BC%8C%E6%B1%82C%E8%AF%AD%E8%A8%80%E7%A8%8B%E5%BA%8F%EF%BC%9F&fr=newsearchlist
					code_verify = (UART_recv_buffer[3] + UART_recv_buffer[4]) * UART_recv_buffer[5];
					UART_send_buffer[3] = code_verify & 0xff;
					UART_send_buffer[4] = (code_verify >> 8) & 0xff;
					UART_send_buffer[5] = (code_verify >> 16) & 0xff;
					UART_send_buffer[6] = (code_verify >> 24) & 0xff;
					UART_send_buffer[7] = 0x0B;
					UART_send_buffer[8] = 0x00;
					UART_send_buffer[9] = 0x00;
					UART_send_buffer[10] = 0x00;
					UART_send_buffer[11] = 0x00;
					frame_verify = UART_send_buffer[2] + UART_send_buffer[3] + UART_send_buffer[4] + UART_send_buffer[5] + \
											   UART_send_buffer[6] + UART_send_buffer[7] + UART_send_buffer[8] + UART_send_buffer[9] + \
												 UART_send_buffer[10];
					UART_send_buffer[12] = frame_verify & 0xff;
					UART_send_buffer[13] = 0x86;

					// send buffer
					HAL_UART_Transmit_DMA(&huart1, (uint8_t *)&UART_send_buffer, 13);   //choose uart line

					if (xSemaphoreTake( exti_xSemaphore, 10000) == pdTRUE) {
						time_origin = xTaskGetTickCount() * portTICK_RATE_MS;
						FieldHandle = osThreadNew(field_task, NULL, &field_attributes);
					}
					else {
						//error message
					}
			}

			return HAL_OK;

		case 0x16:
			if( FieldHandle != NULL ) {
				osThreadTerminate( FieldHandle );
			}
			HAL_TIM_PWM_Stop(&htim3, TIM_CHANNEL_1);
			__HAL_TIM_SET_AUTORELOAD(&htim3, 1333 - 1);
			__HAL_TIM_SET_COMPARE(&htim3, TIM_CHANNEL_1, 100 - 1);
			HAL_TIM_PWM_Start(&htim3, TIM_CHANNEL_1);
	//				pwm_count = 0;

		//config DO6/7/9/10/11/12
			HAL_GPIO_WritePin(GPIOA, GPIO_PIN_15, GPIO_PIN_SET);
			HAL_GPIO_WritePin(GPIOE, GPIO_PIN_0| GPIO_PIN_3 |GPIO_PIN_4|GPIO_PIN_5, GPIO_PIN_SET);
			HAL_GPIO_WritePin(GPIOE,  GPIO_PIN_1, GPIO_PIN_RESET);

			if (xSemaphoreTake( uart_A1_xSemaphore,10000) == pdTRUE) {
					// hand shake
					// fill buffer as in tab3B1
					// function start: repeated code of hand shake sent tab3B1
					UART_send_buffer[0] = 0xA6;
					UART_send_buffer[1] = 0x0D;
					UART_send_buffer[2] = 0xAA;
					//https://zhidao.baidu.com/question/1638675882443131580.html?qbpn=2_2&tx=&word=%E4%BB%8E%E4%B8%80%E4%B8%AA16%E4%BD%8D%E5%8F%98%E9%87%8F%E4%B8%AD%E5%8F%96%E5%87%BA%E9%AB%988%E4%BD%8D%E5%92%8C%E4%BD%8E8%E4%BD%8D%EF%BC%8C%E6%B1%82C%E8%AF%AD%E8%A8%80%E7%A8%8B%E5%BA%8F%EF%BC%9F&fr=newsearchlist
					code_verify = (UART_recv_buffer[3] + UART_recv_buffer[4]) * UART_recv_buffer[5];
					UART_send_buffer[3] = code_verify & 0xff;
					UART_send_buffer[4] = (code_verify >> 8) & 0xff;
					UART_send_buffer[5] = (code_verify >> 16) & 0xff;
					UART_send_buffer[6] = (code_verify >> 24) & 0xff;
					UART_send_buffer[7] = 0x0B;
					UART_send_buffer[8] = 0x00;
					UART_send_buffer[9] = 0x00;
					UART_send_buffer[10] = 0x00;
					UART_send_buffer[11] = 0x00;
					frame_verify = UART_send_buffer[2] + UART_send_buffer[3] + UART_send_buffer[4] + UART_send_buffer[5] + \
											   UART_send_buffer[6] + UART_send_buffer[7] + UART_send_buffer[8] + UART_send_buffer[9] + \
												 UART_send_buffer[10];
					UART_send_buffer[12] = frame_verify & 0xff;
					UART_send_buffer[13] = 0x86;

					// send buffer
					HAL_UART_Transmit_DMA(&huart1, (uint8_t *)&UART_send_buffer, 13);   //choose uart line

					if (xSemaphoreTake( exti_xSemaphore, 10000) == pdTRUE) {
						time_origin = xTaskGetTickCount() * portTICK_RATE_MS;
						FieldHandle = osThreadNew(field_task, NULL, &field_attributes);
					}
					else {
						//error message
					}
			}

			return HAL_OK;

		case 0x17:
			if( FieldHandle != NULL ) {
				osThreadTerminate( FieldHandle );
			}
			HAL_TIM_PWM_Stop(&htim3, TIM_CHANNEL_1);
			__HAL_TIM_SET_AUTORELOAD(&htim3, 1333 - 1);
			__HAL_TIM_SET_COMPARE(&htim3, TIM_CHANNEL_1, 100 - 1);
			HAL_TIM_PWM_Start(&htim3, TIM_CHANNEL_1);
	//				pwm_count = 0;

		//config DO6/7/9/10/11/12
			HAL_GPIO_WritePin(GPIOA, GPIO_PIN_15, GPIO_PIN_SET);
			HAL_GPIO_WritePin(GPIOE, GPIO_PIN_0| GPIO_PIN_3 |GPIO_PIN_4|GPIO_PIN_5, GPIO_PIN_SET);
			HAL_GPIO_WritePin(GPIOE,  GPIO_PIN_1, GPIO_PIN_RESET);

			if (xSemaphoreTake( uart_A1_xSemaphore,10000) == pdTRUE) {
					// hand shake
					// fill buffer as in tab3B1
					// function start: repeated code of hand shake sent tab3B1
					UART_send_buffer[0] = 0xA6;
					UART_send_buffer[1] = 0x0D;
					UART_send_buffer[2] = 0xAA;
					//https://zhidao.baidu.com/question/1638675882443131580.html?qbpn=2_2&tx=&word=%E4%BB%8E%E4%B8%80%E4%B8%AA16%E4%BD%8D%E5%8F%98%E9%87%8F%E4%B8%AD%E5%8F%96%E5%87%BA%E9%AB%988%E4%BD%8D%E5%92%8C%E4%BD%8E8%E4%BD%8D%EF%BC%8C%E6%B1%82C%E8%AF%AD%E8%A8%80%E7%A8%8B%E5%BA%8F%EF%BC%9F&fr=newsearchlist
					code_verify = (UART_recv_buffer[3] + UART_recv_buffer[4]) * UART_recv_buffer[5];
					UART_send_buffer[3] = code_verify & 0xff;
					UART_send_buffer[4] = (code_verify >> 8) & 0xff;
					UART_send_buffer[5] = (code_verify >> 16) & 0xff;
					UART_send_buffer[6] = (code_verify >> 24) & 0xff;
					UART_send_buffer[7] = 0x0B;
					UART_send_buffer[8] = 0x00;
					UART_send_buffer[9] = 0x00;
					UART_send_buffer[10] = 0x00;
					UART_send_buffer[11] = 0x00;
					frame_verify = UART_send_buffer[2] + UART_send_buffer[3] + UART_send_buffer[4] + UART_send_buffer[5] + \
											   UART_send_buffer[6] + UART_send_buffer[7] + UART_send_buffer[8] + UART_send_buffer[9] + \
												 UART_send_buffer[10];
					UART_send_buffer[12] = frame_verify & 0xff;
					UART_send_buffer[13] = 0x86;

					// send buffer
					HAL_UART_Transmit_DMA(&huart1, (uint8_t *)&UART_send_buffer, 13);   //choose uart line

					if (xSemaphoreTake( exti_xSemaphore, 10000) == pdTRUE) {
						time_origin = xTaskGetTickCount() * portTICK_RATE_MS;
						FieldHandle = osThreadNew(field_task, NULL, &field_attributes);
					}
					else {
						//error message
					}
			}

			return HAL_OK;

		case 0x18:
			if( FieldHandle != NULL ) {
				osThreadTerminate( FieldHandle );
			}
			HAL_TIM_PWM_Stop(&htim3, TIM_CHANNEL_1);
			__HAL_TIM_SET_AUTORELOAD(&htim3, 1333 - 1);
			__HAL_TIM_SET_COMPARE(&htim3, TIM_CHANNEL_1, 100 - 1);
			HAL_TIM_PWM_Start(&htim3, TIM_CHANNEL_1);
	//				pwm_count = 0;

		//config DO6/7/9/10/11/12
			HAL_GPIO_WritePin(GPIOA, GPIO_PIN_15, GPIO_PIN_SET);
			HAL_GPIO_WritePin(GPIOE, GPIO_PIN_0| GPIO_PIN_3 |GPIO_PIN_4|GPIO_PIN_5, GPIO_PIN_SET);
			HAL_GPIO_WritePin(GPIOE,  GPIO_PIN_1, GPIO_PIN_RESET);

			if (xSemaphoreTake( uart_A1_xSemaphore,10000) == pdTRUE) {
					// hand shake
					// fill buffer as in tab3B1
					// function start: repeated code of hand shake sent tab3B1
					UART_send_buffer[0] = 0xA6;
					UART_send_buffer[1] = 0x0D;
					UART_send_buffer[2] = 0xAA;
					//https://zhidao.baidu.com/question/1638675882443131580.html?qbpn=2_2&tx=&word=%E4%BB%8E%E4%B8%80%E4%B8%AA16%E4%BD%8D%E5%8F%98%E9%87%8F%E4%B8%AD%E5%8F%96%E5%87%BA%E9%AB%988%E4%BD%8D%E5%92%8C%E4%BD%8E8%E4%BD%8D%EF%BC%8C%E6%B1%82C%E8%AF%AD%E8%A8%80%E7%A8%8B%E5%BA%8F%EF%BC%9F&fr=newsearchlist
					code_verify = (UART_recv_buffer[3] + UART_recv_buffer[4]) * UART_recv_buffer[5];
					UART_send_buffer[3] = code_verify & 0xff;
					UART_send_buffer[4] = (code_verify >> 8) & 0xff;
					UART_send_buffer[5] = (code_verify >> 16) & 0xff;
					UART_send_buffer[6] = (code_verify >> 24) & 0xff;
					UART_send_buffer[7] = 0x0B;
					UART_send_buffer[8] = 0x00;
					UART_send_buffer[9] = 0x00;
					UART_send_buffer[10] = 0x00;
					UART_send_buffer[11] = 0x00;
					frame_verify = UART_send_buffer[2] + UART_send_buffer[3] + UART_send_buffer[4] + UART_send_buffer[5] + \
											   UART_send_buffer[6] + UART_send_buffer[7] + UART_send_buffer[8] + UART_send_buffer[9] + \
												 UART_send_buffer[10];
					UART_send_buffer[12] = frame_verify & 0xff;
					UART_send_buffer[13] = 0x86;

					// send buffer
					HAL_UART_Transmit_DMA(&huart1, (uint8_t *)&UART_send_buffer, 13);   //choose uart line

					if (xSemaphoreTake( exti_xSemaphore, 10000) == pdTRUE) {
						time_origin = xTaskGetTickCount() * portTICK_RATE_MS;
						FieldHandle = osThreadNew(field_task, NULL, &field_attributes);
					}
					else {
						//error message
					}
			}

			return HAL_OK;

		case 0x19:
			if( FieldHandle != NULL ) {
				osThreadTerminate( FieldHandle );
			}
			HAL_TIM_PWM_Stop(&htim3, TIM_CHANNEL_1);
			__HAL_TIM_SET_AUTORELOAD(&htim3, 1333 - 1);
			__HAL_TIM_SET_COMPARE(&htim3, TIM_CHANNEL_1, 100 - 1);
			HAL_TIM_PWM_Start(&htim3, TIM_CHANNEL_1);
	//				pwm_count = 0;

		//config DO6/7/9/10/11/12
			HAL_GPIO_WritePin(GPIOA, GPIO_PIN_15, GPIO_PIN_SET);
			HAL_GPIO_WritePin(GPIOE, GPIO_PIN_0| GPIO_PIN_3 |GPIO_PIN_4|GPIO_PIN_5, GPIO_PIN_SET);
			HAL_GPIO_WritePin(GPIOE,  GPIO_PIN_1, GPIO_PIN_RESET);

			if (xSemaphoreTake( uart_A1_xSemaphore,10000) == pdTRUE) {
					// hand shake
					// fill buffer as in tab3B1
					// function start: repeated code of hand shake sent tab3B1
					UART_send_buffer[0] = 0xA6;
					UART_send_buffer[1] = 0x0D;
					UART_send_buffer[2] = 0xAA;
					//https://zhidao.baidu.com/question/1638675882443131580.html?qbpn=2_2&tx=&word=%E4%BB%8E%E4%B8%80%E4%B8%AA16%E4%BD%8D%E5%8F%98%E9%87%8F%E4%B8%AD%E5%8F%96%E5%87%BA%E9%AB%988%E4%BD%8D%E5%92%8C%E4%BD%8E8%E4%BD%8D%EF%BC%8C%E6%B1%82C%E8%AF%AD%E8%A8%80%E7%A8%8B%E5%BA%8F%EF%BC%9F&fr=newsearchlist
					code_verify = (UART_recv_buffer[3] + UART_recv_buffer[4]) * UART_recv_buffer[5];
					UART_send_buffer[3] = code_verify & 0xff;
					UART_send_buffer[4] = (code_verify >> 8) & 0xff;
					UART_send_buffer[5] = (code_verify >> 16) & 0xff;
					UART_send_buffer[6] = (code_verify >> 24) & 0xff;
					UART_send_buffer[7] = 0x0B;
					UART_send_buffer[8] = 0x00;
					UART_send_buffer[9] = 0x00;
					UART_send_buffer[10] = 0x00;
					UART_send_buffer[11] = 0x00;
					frame_verify = UART_send_buffer[2] + UART_send_buffer[3] + UART_send_buffer[4] + UART_send_buffer[5] + \
											   UART_send_buffer[6] + UART_send_buffer[7] + UART_send_buffer[8] + UART_send_buffer[9] + \
												 UART_send_buffer[10];
					UART_send_buffer[12] = frame_verify & 0xff;
					UART_send_buffer[13] = 0x86;

					// send buffer
					HAL_UART_Transmit_DMA(&huart1, (uint8_t *)&UART_send_buffer, 13);   //choose uart line

					if (xSemaphoreTake( exti_xSemaphore, 10000) == pdTRUE) {
						time_origin = xTaskGetTickCount() * portTICK_RATE_MS;
						FieldHandle = osThreadNew(field_task, NULL, &field_attributes);
					}
					else {
						//error message
					}
			}

			return HAL_OK;

		case 0x1A:
			if( FieldHandle != NULL ) {
				osThreadTerminate( FieldHandle );
			}
			HAL_TIM_PWM_Stop(&htim3, TIM_CHANNEL_1);
			__HAL_TIM_SET_AUTORELOAD(&htim3, 1333 - 1);
			__HAL_TIM_SET_COMPARE(&htim3, TIM_CHANNEL_1, 100 - 1);
			HAL_TIM_PWM_Start(&htim3, TIM_CHANNEL_1);
	//				pwm_count = 0;

		//config DO6/7/9/10/11/12
			HAL_GPIO_WritePin(GPIOA, GPIO_PIN_15, GPIO_PIN_SET);
			HAL_GPIO_WritePin(GPIOE, GPIO_PIN_0 |GPIO_PIN_4|GPIO_PIN_5, GPIO_PIN_SET);
			HAL_GPIO_WritePin(GPIOE,  GPIO_PIN_1| GPIO_PIN_3, GPIO_PIN_RESET);

			if (xSemaphoreTake( uart_A1_xSemaphore,10000) == pdTRUE) {
					// hand shake
					// fill buffer as in tab3B1
					// function start: repeated code of hand shake sent tab3B1
					UART_send_buffer[0] = 0xA6;
					UART_send_buffer[1] = 0x0D;
					UART_send_buffer[2] = 0xAA;
					//https://zhidao.baidu.com/question/1638675882443131580.html?qbpn=2_2&tx=&word=%E4%BB%8E%E4%B8%80%E4%B8%AA16%E4%BD%8D%E5%8F%98%E9%87%8F%E4%B8%AD%E5%8F%96%E5%87%BA%E9%AB%988%E4%BD%8D%E5%92%8C%E4%BD%8E8%E4%BD%8D%EF%BC%8C%E6%B1%82C%E8%AF%AD%E8%A8%80%E7%A8%8B%E5%BA%8F%EF%BC%9F&fr=newsearchlist
					code_verify = (UART_recv_buffer[3] + UART_recv_buffer[4]) * UART_recv_buffer[5];
					UART_send_buffer[3] = code_verify & 0xff;
					UART_send_buffer[4] = (code_verify >> 8) & 0xff;
					UART_send_buffer[5] = (code_verify >> 16) & 0xff;
					UART_send_buffer[6] = (code_verify >> 24) & 0xff;
					UART_send_buffer[7] = 0x0B;
					UART_send_buffer[8] = 0x00;
					UART_send_buffer[9] = 0x00;
					UART_send_buffer[10] = 0x00;
					UART_send_buffer[11] = 0x00;
					frame_verify = UART_send_buffer[2] + UART_send_buffer[3] + UART_send_buffer[4] + UART_send_buffer[5] + \
											   UART_send_buffer[6] + UART_send_buffer[7] + UART_send_buffer[8] + UART_send_buffer[9] + \
												 UART_send_buffer[10];
					UART_send_buffer[12] = frame_verify & 0xff;
					UART_send_buffer[13] = 0x86;

					// send buffer
					HAL_UART_Transmit_DMA(&huart1, (uint8_t *)&UART_send_buffer, 13);   //choose uart line

					if (xSemaphoreTake( exti_xSemaphore, 10000) == pdTRUE) {
						time_origin = xTaskGetTickCount() * portTICK_RATE_MS;
						FieldHandle = osThreadNew(field_task, NULL, &field_attributes);
					}
					else {
						//error message
					}
			}

			return HAL_OK;

		case 0x1B:
			if( FieldHandle != NULL ) {
				osThreadTerminate( FieldHandle );
			}
			HAL_TIM_PWM_Stop(&htim3, TIM_CHANNEL_1);
			__HAL_TIM_SET_AUTORELOAD(&htim3, 1333 - 1);
			__HAL_TIM_SET_COMPARE(&htim3, TIM_CHANNEL_1, 100 - 1);
			HAL_TIM_PWM_Start(&htim3, TIM_CHANNEL_1);
	//				pwm_count = 0;

		//config DO6/7/9/10/11/12
			HAL_GPIO_WritePin(GPIOA, GPIO_PIN_15, GPIO_PIN_SET);
			HAL_GPIO_WritePin(GPIOE, GPIO_PIN_0| GPIO_PIN_3 |GPIO_PIN_4|GPIO_PIN_5, GPIO_PIN_SET);
			HAL_GPIO_WritePin(GPIOE,  GPIO_PIN_1, GPIO_PIN_RESET);

			if (xSemaphoreTake( uart_A1_xSemaphore,10000) == pdTRUE) {
					// hand shake
					// fill buffer as in tab3B1
					// function start: repeated code of hand shake sent tab3B1
					UART_send_buffer[0] = 0xA6;
					UART_send_buffer[1] = 0x0D;
					UART_send_buffer[2] = 0xAA;
					//https://zhidao.baidu.com/question/1638675882443131580.html?qbpn=2_2&tx=&word=%E4%BB%8E%E4%B8%80%E4%B8%AA16%E4%BD%8D%E5%8F%98%E9%87%8F%E4%B8%AD%E5%8F%96%E5%87%BA%E9%AB%988%E4%BD%8D%E5%92%8C%E4%BD%8E8%E4%BD%8D%EF%BC%8C%E6%B1%82C%E8%AF%AD%E8%A8%80%E7%A8%8B%E5%BA%8F%EF%BC%9F&fr=newsearchlist
					code_verify = (UART_recv_buffer[3] + UART_recv_buffer[4]) * UART_recv_buffer[5];
					UART_send_buffer[3] = code_verify & 0xff;
					UART_send_buffer[4] = (code_verify >> 8) & 0xff;
					UART_send_buffer[5] = (code_verify >> 16) & 0xff;
					UART_send_buffer[6] = (code_verify >> 24) & 0xff;
					UART_send_buffer[7] = 0x0B;
					UART_send_buffer[8] = 0x00;
					UART_send_buffer[9] = 0x00;
					UART_send_buffer[10] = 0x00;
					UART_send_buffer[11] = 0x00;
					frame_verify = UART_send_buffer[2] + UART_send_buffer[3] + UART_send_buffer[4] + UART_send_buffer[5] + \
											   UART_send_buffer[6] + UART_send_buffer[7] + UART_send_buffer[8] + UART_send_buffer[9] + \
												 UART_send_buffer[10];
					UART_send_buffer[12] = frame_verify & 0xff;
					UART_send_buffer[13] = 0x86;

					// send buffer
					HAL_UART_Transmit_DMA(&huart1, (uint8_t *)&UART_send_buffer, 13);   //choose uart line

					if (xSemaphoreTake( exti_xSemaphore, 10000) == pdTRUE) {
						time_origin = xTaskGetTickCount() * portTICK_RATE_MS;
						FieldHandle = osThreadNew(field_task, NULL, &field_attributes);
					}
					else {
						//error message
					}
			}

			return HAL_OK;

		case 0x1D:
			if( FieldHandle != NULL ) {
				osThreadTerminate( FieldHandle );
			}
			HAL_TIM_PWM_Stop(&htim3, TIM_CHANNEL_1);
//			__HAL_TIM_SET_AUTORELOAD(&htim3, 1400 - 1);
//			__HAL_TIM_SET_COMPARE(&htim3, TIM_CHANNEL_1, 100 - 1);
//			HAL_TIM_PWM_Start(&htim3, TIM_CHANNEL_1);
	//				pwm_count = 0;

		//config DO6/7/9/10/11/12
			HAL_GPIO_WritePin(GPIOA, GPIO_PIN_15, GPIO_PIN_SET);
			HAL_GPIO_WritePin(GPIOE, GPIO_PIN_0 |GPIO_PIN_4|GPIO_PIN_5, GPIO_PIN_SET);
			HAL_GPIO_WritePin(GPIOE,  GPIO_PIN_1| GPIO_PIN_3, GPIO_PIN_RESET);

			if (xSemaphoreTake( uart_A1_xSemaphore,10000) == pdTRUE) {
					// hand shake
					// fill buffer as in tab3B1
					// function start: repeated code of hand shake sent tab3B1
					UART_send_buffer[0] = 0xA6;
					UART_send_buffer[1] = 0x0D;
					UART_send_buffer[2] = 0xAA;
					//https://zhidao.baidu.com/question/1638675882443131580.html?qbpn=2_2&tx=&word=%E4%BB%8E%E4%B8%80%E4%B8%AA16%E4%BD%8D%E5%8F%98%E9%87%8F%E4%B8%AD%E5%8F%96%E5%87%BA%E9%AB%988%E4%BD%8D%E5%92%8C%E4%BD%8E8%E4%BD%8D%EF%BC%8C%E6%B1%82C%E8%AF%AD%E8%A8%80%E7%A8%8B%E5%BA%8F%EF%BC%9F&fr=newsearchlist
					code_verify = (UART_recv_buffer[3] + UART_recv_buffer[4]) * UART_recv_buffer[5];
					UART_send_buffer[3] = code_verify & 0xff;
					UART_send_buffer[4] = (code_verify >> 8) & 0xff;
					UART_send_buffer[5] = (code_verify >> 16) & 0xff;
					UART_send_buffer[6] = (code_verify >> 24) & 0xff;
					UART_send_buffer[7] = 0x0B;
					UART_send_buffer[8] = 0x00;
					UART_send_buffer[9] = 0x00;
					UART_send_buffer[10] = 0x00;
					UART_send_buffer[11] = 0x00;
					frame_verify = UART_send_buffer[2] + UART_send_buffer[3] + UART_send_buffer[4] + UART_send_buffer[5] + \
											   UART_send_buffer[6] + UART_send_buffer[7] + UART_send_buffer[8] + UART_send_buffer[9] + \
												 UART_send_buffer[10];
					UART_send_buffer[12] = frame_verify & 0xff;
					UART_send_buffer[13] = 0x86;

					// send buffer
					HAL_UART_Transmit_DMA(&huart1, (uint8_t *)&UART_send_buffer, 13);   //choose uart line

					if (xSemaphoreTake( exti_xSemaphore, 10000) == pdTRUE) {
						time_origin = xTaskGetTickCount() * portTICK_RATE_MS;
						FieldHandle = osThreadNew(field_task, NULL, &field_attributes);
						__HAL_TIM_SET_AUTORELOAD(&htim3, 1400 - 1);
						__HAL_TIM_SET_COMPARE(&htim3, TIM_CHANNEL_1, 100 - 1);
						HAL_TIM_OC_Start_IT(&htim3, TIM_CHANNEL_1);
						HAL_TIM_PWM_Start(&htim3, TIM_CHANNEL_1);
					}
					else {
						//error message
					}
			}

			return HAL_OK;

		case 0x1F:
			if( FieldHandle != NULL ) {
				osThreadTerminate( FieldHandle );
			}
			HAL_TIM_PWM_Stop(&htim3, TIM_CHANNEL_1);
//			__HAL_TIM_SET_AUTORELOAD(&htim3, 1400 - 1);
//			__HAL_TIM_SET_COMPARE(&htim3, TIM_CHANNEL_1, 100 - 1);
//			HAL_TIM_PWM_Start(&htim3, TIM_CHANNEL_1);
	//				pwm_count = 0;

		//config DO6/7/9/10/11/12
			HAL_GPIO_WritePin(GPIOA, GPIO_PIN_15, GPIO_PIN_SET);
			HAL_GPIO_WritePin(GPIOE, GPIO_PIN_0| GPIO_PIN_3 |GPIO_PIN_4|GPIO_PIN_5, GPIO_PIN_SET);
			HAL_GPIO_WritePin(GPIOE,  GPIO_PIN_1, GPIO_PIN_RESET);

			if (xSemaphoreTake( uart_A1_xSemaphore,10000) == pdTRUE) {
					// hand shake
					// fill buffer as in tab3B1
					// function start: repeated code of hand shake sent tab3B1
					UART_send_buffer[0] = 0xA6;
					UART_send_buffer[1] = 0x0D;
					UART_send_buffer[2] = 0xAA;
					//https://zhidao.baidu.com/question/1638675882443131580.html?qbpn=2_2&tx=&word=%E4%BB%8E%E4%B8%80%E4%B8%AA16%E4%BD%8D%E5%8F%98%E9%87%8F%E4%B8%AD%E5%8F%96%E5%87%BA%E9%AB%988%E4%BD%8D%E5%92%8C%E4%BD%8E8%E4%BD%8D%EF%BC%8C%E6%B1%82C%E8%AF%AD%E8%A8%80%E7%A8%8B%E5%BA%8F%EF%BC%9F&fr=newsearchlist
					code_verify = (UART_recv_buffer[3] + UART_recv_buffer[4]) * UART_recv_buffer[5];
					UART_send_buffer[3] = code_verify & 0xff;
					UART_send_buffer[4] = (code_verify >> 8) & 0xff;
					UART_send_buffer[5] = (code_verify >> 16) & 0xff;
					UART_send_buffer[6] = (code_verify >> 24) & 0xff;
					UART_send_buffer[7] = 0x0B;
					UART_send_buffer[8] = 0x00;
					UART_send_buffer[9] = 0x00;
					UART_send_buffer[10] = 0x00;
					UART_send_buffer[11] = 0x00;
					frame_verify = UART_send_buffer[2] + UART_send_buffer[3] + UART_send_buffer[4] + UART_send_buffer[5] + \
											   UART_send_buffer[6] + UART_send_buffer[7] + UART_send_buffer[8] + UART_send_buffer[9] + \
												 UART_send_buffer[10];
					UART_send_buffer[12] = frame_verify & 0xff;
					UART_send_buffer[13] = 0x86;

					// send buffer
					HAL_UART_Transmit_DMA(&huart1, (uint8_t *)&UART_send_buffer, 13);   //choose uart line

					if (xSemaphoreTake( exti_xSemaphore, 10000) == pdTRUE) {
						time_origin = xTaskGetTickCount() * portTICK_RATE_MS;
						FieldHandle = osThreadNew(field_task, NULL, &field_attributes);
						__HAL_TIM_SET_AUTORELOAD(&htim3, 1400 - 1);
						__HAL_TIM_SET_COMPARE(&htim3, TIM_CHANNEL_1, 100 - 1);
						HAL_TIM_OC_Start_IT(&htim3, TIM_CHANNEL_1);
						HAL_TIM_PWM_Start(&htim3, TIM_CHANNEL_1);					}
					else {
						//error message
					}
			}

			return HAL_OK;

		case 0x20:
			if( FieldHandle != NULL ) {
				osThreadTerminate( FieldHandle );
			}
//			__HAL_TIM_SET_AUTORELOAD(&htim3, 1333 - 1);
			__HAL_TIM_SET_COMPARE(&htim3, TIM_CHANNEL_1, 0);
			HAL_TIM_PWM_Stop(&htim3, TIM_CHANNEL_1);
	//				pwm_count = 0;

		//config DO6/7/9/10/11/12
			HAL_GPIO_WritePin(GPIOA, GPIO_PIN_15, GPIO_PIN_SET);
			HAL_GPIO_WritePin(GPIOE,  GPIO_PIN_1|GPIO_PIN_3 , GPIO_PIN_SET);
			HAL_GPIO_WritePin(GPIOE, GPIO_PIN_0|GPIO_PIN_4|GPIO_PIN_5 , GPIO_PIN_RESET);

			if (xSemaphoreTake( uart_A1_xSemaphore,10000) == pdTRUE) {
					// hand shake
					// fill buffer as in tab3B1
					// function start: repeated code of hand shake sent tab3B1
					UART_send_buffer[0] = 0xA6;
					UART_send_buffer[1] = 0x0D;
					UART_send_buffer[2] = 0xAA;
					//https://zhidao.baidu.com/question/1638675882443131580.html?qbpn=2_2&tx=&word=%E4%BB%8E%E4%B8%80%E4%B8%AA16%E4%BD%8D%E5%8F%98%E9%87%8F%E4%B8%AD%E5%8F%96%E5%87%BA%E9%AB%988%E4%BD%8D%E5%92%8C%E4%BD%8E8%E4%BD%8D%EF%BC%8C%E6%B1%82C%E8%AF%AD%E8%A8%80%E7%A8%8B%E5%BA%8F%EF%BC%9F&fr=newsearchlist
					code_verify = (UART_recv_buffer[3] + UART_recv_buffer[4]) * UART_recv_buffer[5];
					UART_send_buffer[3] = code_verify & 0xff;
					UART_send_buffer[4] = (code_verify >> 8) & 0xff;
					UART_send_buffer[5] = (code_verify >> 16) & 0xff;
					UART_send_buffer[6] = (code_verify >> 24) & 0xff;
					UART_send_buffer[7] = 0x0B;
					UART_send_buffer[8] = 0x00;
					UART_send_buffer[9] = 0x00;
					UART_send_buffer[10] = 0x00;
					UART_send_buffer[11] = 0x00;
					frame_verify = UART_send_buffer[2] + UART_send_buffer[3] + UART_send_buffer[4] + UART_send_buffer[5] + \
											   UART_send_buffer[6] + UART_send_buffer[7] + UART_send_buffer[8] + UART_send_buffer[9] + \
												 UART_send_buffer[10];
					UART_send_buffer[12] = frame_verify & 0xff;
					UART_send_buffer[13] = 0x86;

					// send buffer
					HAL_UART_Transmit_DMA(&huart1, (uint8_t *)&UART_send_buffer, 13);   //choose uart line

					if (xSemaphoreTake( exti_xSemaphore, 10000) == pdTRUE) {
						time_origin = xTaskGetTickCount() * portTICK_RATE_MS;
						FieldHandle = osThreadNew(field_task, NULL, &field_attributes);
					}
					else {
						//error message
					}
			}

			return HAL_OK;

		case 0x21:
			if( FieldHandle != NULL ) {
				osThreadTerminate( FieldHandle );
			}
//			__HAL_TIM_SET_AUTORELOAD(&htim3, 1333 - 1);
			__HAL_TIM_SET_COMPARE(&htim3, TIM_CHANNEL_1, 0);
			HAL_TIM_PWM_Stop(&htim3, TIM_CHANNEL_1);
	//				pwm_count = 0;

		//config DO6/7/9/10/11/12
			HAL_GPIO_WritePin(GPIOA, GPIO_PIN_15, GPIO_PIN_SET);
			HAL_GPIO_WritePin(GPIOE, GPIO_PIN_0|GPIO_PIN_3 |GPIO_PIN_4|GPIO_PIN_5 , GPIO_PIN_SET);
			HAL_GPIO_WritePin(GPIOE, GPIO_PIN_1 , GPIO_PIN_RESET);

			if (xSemaphoreTake( uart_A1_xSemaphore,10000) == pdTRUE) {
					// hand shake
					// fill buffer as in tab3B1
					// function start: repeated code of hand shake sent tab3B1
					UART_send_buffer[0] = 0xA6;
					UART_send_buffer[1] = 0x0D;
					UART_send_buffer[2] = 0xAA;
					//https://zhidao.baidu.com/question/1638675882443131580.html?qbpn=2_2&tx=&word=%E4%BB%8E%E4%B8%80%E4%B8%AA16%E4%BD%8D%E5%8F%98%E9%87%8F%E4%B8%AD%E5%8F%96%E5%87%BA%E9%AB%988%E4%BD%8D%E5%92%8C%E4%BD%8E8%E4%BD%8D%EF%BC%8C%E6%B1%82C%E8%AF%AD%E8%A8%80%E7%A8%8B%E5%BA%8F%EF%BC%9F&fr=newsearchlist
					code_verify = (UART_recv_buffer[3] + UART_recv_buffer[4]) * UART_recv_buffer[5];
					UART_send_buffer[3] = code_verify & 0xff;
					UART_send_buffer[4] = (code_verify >> 8) & 0xff;
					UART_send_buffer[5] = (code_verify >> 16) & 0xff;
					UART_send_buffer[6] = (code_verify >> 24) & 0xff;
					UART_send_buffer[7] = 0x0B;
					UART_send_buffer[8] = 0x00;
					UART_send_buffer[9] = 0x00;
					UART_send_buffer[10] = 0x00;
					UART_send_buffer[11] = 0x00;
					frame_verify = UART_send_buffer[2] + UART_send_buffer[3] + UART_send_buffer[4] + UART_send_buffer[5] + \
											   UART_send_buffer[6] + UART_send_buffer[7] + UART_send_buffer[8] + UART_send_buffer[9] + \
												 UART_send_buffer[10];
					UART_send_buffer[12] = frame_verify & 0xff;
					UART_send_buffer[13] = 0x86;

					// send buffer
					HAL_UART_Transmit_DMA(&huart1, (uint8_t *)&UART_send_buffer, 13);   //choose uart line

					if (xSemaphoreTake( exti_xSemaphore, 10000) == pdTRUE) {
						time_origin = xTaskGetTickCount() * portTICK_RATE_MS;
						FieldHandle = osThreadNew(field_task, NULL, &field_attributes);
					}
					else {
						//error message
					}
			}

			return HAL_OK;

		case 0x22:
			if( FieldHandle != NULL ) {
				osThreadTerminate( FieldHandle );
			}
			HAL_TIM_PWM_Stop(&htim3, TIM_CHANNEL_1);
			__HAL_TIM_SET_AUTORELOAD(&htim3, 1333 - 1);
			__HAL_TIM_SET_COMPARE(&htim3, TIM_CHANNEL_1, 100 - 1);
			HAL_TIM_PWM_Start(&htim3, TIM_CHANNEL_1);
	//				pwm_count = 0;

		//config DO6/7/9/10/11/12
			HAL_GPIO_WritePin(GPIOA, GPIO_PIN_15, GPIO_PIN_SET);
			HAL_GPIO_WritePin(GPIOE, GPIO_PIN_1 |GPIO_PIN_3, GPIO_PIN_SET);
			HAL_GPIO_WritePin(GPIOE,GPIO_PIN_0 |GPIO_PIN_4|GPIO_PIN_5  , GPIO_PIN_RESET);

			if (xSemaphoreTake( uart_A1_xSemaphore,10000) == pdTRUE) {
					// hand shake
					// fill buffer as in tab3B1
					// function start: repeated code of hand shake sent tab3B1
					UART_send_buffer[0] = 0xA6;
					UART_send_buffer[1] = 0x0D;
					UART_send_buffer[2] = 0xAA;
					//https://zhidao.baidu.com/question/1638675882443131580.html?qbpn=2_2&tx=&word=%E4%BB%8E%E4%B8%80%E4%B8%AA16%E4%BD%8D%E5%8F%98%E9%87%8F%E4%B8%AD%E5%8F%96%E5%87%BA%E9%AB%988%E4%BD%8D%E5%92%8C%E4%BD%8E8%E4%BD%8D%EF%BC%8C%E6%B1%82C%E8%AF%AD%E8%A8%80%E7%A8%8B%E5%BA%8F%EF%BC%9F&fr=newsearchlist
					code_verify = (UART_recv_buffer[3] + UART_recv_buffer[4]) * UART_recv_buffer[5];
					UART_send_buffer[3] = code_verify & 0xff;
					UART_send_buffer[4] = (code_verify >> 8) & 0xff;
					UART_send_buffer[5] = (code_verify >> 16) & 0xff;
					UART_send_buffer[6] = (code_verify >> 24) & 0xff;
					UART_send_buffer[7] = 0x0B;
					UART_send_buffer[8] = 0x00;
					UART_send_buffer[9] = 0x00;
					UART_send_buffer[10] = 0x00;
					UART_send_buffer[11] = 0x00;
					frame_verify = UART_send_buffer[2] + UART_send_buffer[3] + UART_send_buffer[4] + UART_send_buffer[5] + \
											   UART_send_buffer[6] + UART_send_buffer[7] + UART_send_buffer[8] + UART_send_buffer[9] + \
												 UART_send_buffer[10];
					UART_send_buffer[12] = frame_verify & 0xff;
					UART_send_buffer[13] = 0x86;

					// send buffer
					HAL_UART_Transmit_DMA(&huart1, (uint8_t *)&UART_send_buffer, 13);   //choose uart line

					if (xSemaphoreTake( exti_xSemaphore, 10000) == pdTRUE) {
						time_origin = xTaskGetTickCount() * portTICK_RATE_MS;
						FieldHandle = osThreadNew(field_task, NULL, &field_attributes);
					}
					else {
						//error message
					}
			}

			return HAL_OK;

		case 0x23:
			if( FieldHandle != NULL ) {
				osThreadTerminate( FieldHandle );
			}
			HAL_TIM_PWM_Stop(&htim3, TIM_CHANNEL_1);
			__HAL_TIM_SET_AUTORELOAD(&htim3, 1333 - 1);
			__HAL_TIM_SET_COMPARE(&htim3, TIM_CHANNEL_1, 100 - 1);
			HAL_TIM_PWM_Start(&htim3, TIM_CHANNEL_1);
	//				pwm_count = 0;

		//config DO6/7/9/10/11/12
			HAL_GPIO_WritePin(GPIOA, GPIO_PIN_15, GPIO_PIN_SET);
			HAL_GPIO_WritePin(GPIOE, GPIO_PIN_0|GPIO_PIN_3 |GPIO_PIN_4|GPIO_PIN_5 , GPIO_PIN_SET);
			HAL_GPIO_WritePin(GPIOE, GPIO_PIN_1 , GPIO_PIN_RESET);

			if (xSemaphoreTake( uart_A1_xSemaphore,10000) == pdTRUE) {
					// hand shake
					// fill buffer as in tab3B1
					// function start: repeated code of hand shake sent tab3B1
					UART_send_buffer[0] = 0xA6;
					UART_send_buffer[1] = 0x0D;
					UART_send_buffer[2] = 0xAA;
					//https://zhidao.baidu.com/question/1638675882443131580.html?qbpn=2_2&tx=&word=%E4%BB%8E%E4%B8%80%E4%B8%AA16%E4%BD%8D%E5%8F%98%E9%87%8F%E4%B8%AD%E5%8F%96%E5%87%BA%E9%AB%988%E4%BD%8D%E5%92%8C%E4%BD%8E8%E4%BD%8D%EF%BC%8C%E6%B1%82C%E8%AF%AD%E8%A8%80%E7%A8%8B%E5%BA%8F%EF%BC%9F&fr=newsearchlist
					code_verify = (UART_recv_buffer[3] + UART_recv_buffer[4]) * UART_recv_buffer[5];
					UART_send_buffer[3] = code_verify & 0xff;
					UART_send_buffer[4] = (code_verify >> 8) & 0xff;
					UART_send_buffer[5] = (code_verify >> 16) & 0xff;
					UART_send_buffer[6] = (code_verify >> 24) & 0xff;
					UART_send_buffer[7] = 0x0B;
					UART_send_buffer[8] = 0x00;
					UART_send_buffer[9] = 0x00;
					UART_send_buffer[10] = 0x00;
					UART_send_buffer[11] = 0x00;
					frame_verify = UART_send_buffer[2] + UART_send_buffer[3] + UART_send_buffer[4] + UART_send_buffer[5] + \
											   UART_send_buffer[6] + UART_send_buffer[7] + UART_send_buffer[8] + UART_send_buffer[9] + \
												 UART_send_buffer[10];
					UART_send_buffer[12] = frame_verify & 0xff;
					UART_send_buffer[13] = 0x86;

					// send buffer
					HAL_UART_Transmit_DMA(&huart1, (uint8_t *)&UART_send_buffer, 13);   //choose uart line

					if (xSemaphoreTake( exti_xSemaphore, 10000) == pdTRUE) {
						time_origin = xTaskGetTickCount() * portTICK_RATE_MS;
						FieldHandle = osThreadNew(field_task, NULL, &field_attributes);
					}
					else {
						//error message
					}
			}

			return HAL_OK;

		case 0x24:
			if( FieldHandle != NULL ) {
				osThreadTerminate( FieldHandle );
			}
//			__HAL_TIM_SET_AUTORELOAD(&htim3, 1333 - 1);
			__HAL_TIM_SET_COMPARE(&htim3, TIM_CHANNEL_1, 0);
			HAL_TIM_PWM_Stop(&htim3, TIM_CHANNEL_1);
	//				pwm_count = 0;

		//config DO6/7/9/10/11/12
			HAL_GPIO_WritePin(GPIOA, GPIO_PIN_15, GPIO_PIN_SET);
			HAL_GPIO_WritePin(GPIOE, GPIO_PIN_1|GPIO_PIN_5 , GPIO_PIN_SET);
			HAL_GPIO_WritePin(GPIOE, GPIO_PIN_0|GPIO_PIN_3 |GPIO_PIN_4 , GPIO_PIN_RESET);

			if (xSemaphoreTake( uart_A1_xSemaphore,10000) == pdTRUE) {
					// hand shake
					// fill buffer as in tab3B1
					// function start: repeated code of hand shake sent tab3B1
					UART_send_buffer[0] = 0xA6;
					UART_send_buffer[1] = 0x0D;
					UART_send_buffer[2] = 0xAA;
					//https://zhidao.baidu.com/question/1638675882443131580.html?qbpn=2_2&tx=&word=%E4%BB%8E%E4%B8%80%E4%B8%AA16%E4%BD%8D%E5%8F%98%E9%87%8F%E4%B8%AD%E5%8F%96%E5%87%BA%E9%AB%988%E4%BD%8D%E5%92%8C%E4%BD%8E8%E4%BD%8D%EF%BC%8C%E6%B1%82C%E8%AF%AD%E8%A8%80%E7%A8%8B%E5%BA%8F%EF%BC%9F&fr=newsearchlist
					code_verify = (UART_recv_buffer[3] + UART_recv_buffer[4]) * UART_recv_buffer[5];
					UART_send_buffer[3] = code_verify & 0xff;
					UART_send_buffer[4] = (code_verify >> 8) & 0xff;
					UART_send_buffer[5] = (code_verify >> 16) & 0xff;
					UART_send_buffer[6] = (code_verify >> 24) & 0xff;
					UART_send_buffer[7] = 0x0B;
					UART_send_buffer[8] = 0x00;
					UART_send_buffer[9] = 0x00;
					UART_send_buffer[10] = 0x00;
					UART_send_buffer[11] = 0x00;
					frame_verify = UART_send_buffer[2] + UART_send_buffer[3] + UART_send_buffer[4] + UART_send_buffer[5] + \
											   UART_send_buffer[6] + UART_send_buffer[7] + UART_send_buffer[8] + UART_send_buffer[9] + \
												 UART_send_buffer[10];
					UART_send_buffer[12] = frame_verify & 0xff;
					UART_send_buffer[13] = 0x86;

					// send buffer
					HAL_UART_Transmit_DMA(&huart1, (uint8_t *)&UART_send_buffer, 13);   //choose uart line

					if (xSemaphoreTake( exti_xSemaphore, 10000) == pdTRUE) {
						time_origin = xTaskGetTickCount() * portTICK_RATE_MS;
						FieldHandle = osThreadNew(field_task, NULL, &field_attributes);
					}
					else {
						//error message
					}
			}

			return HAL_OK;

		default:
//			HAL_TIM_OC_Start_IT(&htim3, TIM_CHANNEL_1);
			break;
	}
	return HAL_OK;
}

void HAL_TIM_IC_CaptureCallback(TIM_HandleTypeDef *htim)
{
//	 portBASE_TYPE xHigherPriorityTaskWoken;
	 if(htim->Instance==TIM3){
      switch(pwm_count){
			case 0 :
						__HAL_TIM_SET_AUTORELOAD(&htim3, 1510 - 1);
						pwm_count++;
						break;
			case 1 :
						__HAL_TIM_SET_AUTORELOAD(&htim3, 1600 - 1);
						pwm_count++;
						break;
			case 2 :
						__HAL_TIM_SET_AUTORELOAD(&htim3, 1570 - 1);
						pwm_count++;
						break;
			case 3 :
						__HAL_TIM_SET_AUTORELOAD(&htim3, 1510 - 1);
						pwm_count++;
						break;
			case 4 :
						__HAL_TIM_SET_AUTORELOAD(&htim3, 1470 - 1);
						pwm_count++;
						break;
			case 5 :
						__HAL_TIM_SET_AUTORELOAD(&htim3, 1380 - 1);
						pwm_count++;
						break;
			case 6 :
						__HAL_TIM_SET_AUTORELOAD(&htim3, 1300 - 1);
						pwm_count++;
						break;
			case 7 :
						__HAL_TIM_SET_AUTORELOAD(&htim3, 1210 - 1);
						pwm_count++;
						break;
			case 8 :
						__HAL_TIM_SET_AUTORELOAD(&htim3, 1160 - 1);
						pwm_count++;
						break;
			case 9 :
						__HAL_TIM_SET_AUTORELOAD(&htim3, 1130 - 1);
						pwm_count++;
						break;
			case 10 :
						__HAL_TIM_SET_AUTORELOAD(&htim3, 1170 - 1);
						pwm_count++;
						break;
			case 11 :
						__HAL_TIM_SET_AUTORELOAD(&htim3, 1090 - 1);
						pwm_count++;
						break;
			case 12 :
						__HAL_TIM_SET_AUTORELOAD(&htim3, 1090 - 1);
						pwm_count++;
						break;
			case 13 :
						__HAL_TIM_SET_AUTORELOAD(&htim3, 1333 - 1);
						pwm_count=0;
						HAL_TIM_OC_Stop_IT(&htim3, TIM_CHANNEL_1);
//						xSemaphoreGiveFromISR( pwm_xSemaphore, &xHigherPriorityTaskWoken );
						break;
			default:
						pwm_count=0;
						HAL_TIM_OC_Stop_IT(&htim3, TIM_CHANNEL_1);
						break;
			}
	 }
}

void field_task(void *argument){
	portTickType temp_t;
	int16_t epsilon;
	int16_t beta;
	unsigned int frame_verify;
	do {
		temp_t = xTaskGetTickCount() * portTICK_RATE_MS - time_origin;
		//large field
		if ( temp_t <= 3520 ) {
			UART_field_buffer[0] = 0xA6;
			UART_field_buffer[1] = 0x10;
			UART_field_buffer[2] = 0x81;
			UART_field_buffer[3] = temp_t & 0xff;
			UART_field_buffer[4] = (temp_t >> 8) & 0xff;
			UART_field_buffer[5] = (temp_t >> 16) & 0xff;
			UART_field_buffer[6] = (temp_t >> 24) & 0xff;
			switch (current_command) {
				case 0x1D:
					epsilon = 0;
					beta = -21537;
					UART_field_buffer[7] = epsilon & 0xff;
					UART_field_buffer[8] = (epsilon >> 8) & 0xff;
					UART_field_buffer[9] = beta & 0xff;
					UART_field_buffer[10] = (beta >> 8) & 0xff;
					break;

				case 0x1F:
					epsilon = 0;
					beta = -21537;
					UART_field_buffer[7] = epsilon & 0xff;
					UART_field_buffer[8] = (epsilon >> 8) & 0xff;
					UART_field_buffer[9] = beta & 0xff;
					UART_field_buffer[10] = (beta >> 8) & 0xff;
					break;
				case 0x01:
				  break;
				case 0x02:
				  break;
				case 0x03:
					epsilon = 0;
					beta = 0;
					UART_field_buffer[7] = epsilon & 0xff;
					UART_field_buffer[8] = (epsilon >> 8) & 0xff;
					UART_field_buffer[9] = beta & 0xff;
					UART_field_buffer[10] = (beta >> 8) & 0xff;
				  break;
				case 0x04:
					epsilon = 0;
					beta = 0;
					UART_field_buffer[7] = epsilon & 0xff;
					UART_field_buffer[8] = (epsilon >> 8) & 0xff;
					UART_field_buffer[9] = beta & 0xff;
					UART_field_buffer[10] = (beta >> 8) & 0xff;
				  break;
				case 0x05:
					epsilon = 0;
					beta = 0;
					UART_field_buffer[7] = epsilon & 0xff;
					UART_field_buffer[8] = (epsilon >> 8) & 0xff;
					UART_field_buffer[9] = beta & 0xff;
					UART_field_buffer[10] = (beta >> 8) & 0xff;
				  break;
				case 0x06:
					epsilon = 10338;
					beta = 0;
					UART_field_buffer[7] = epsilon & 0xff;
					UART_field_buffer[8] = (epsilon >> 8) & 0xff;
					UART_field_buffer[9] = beta & 0xff;
					UART_field_buffer[10] = (beta >> 8) & 0xff;
				  break;
				case 0x07:
					epsilon = 11199;
					beta = 0;
					UART_field_buffer[7] = epsilon & 0xff;
					UART_field_buffer[8] = (epsilon >> 8) & 0xff;
					UART_field_buffer[9] = beta & 0xff;
					UART_field_buffer[10] = (beta >> 8) & 0xff;
				  break;
				case 0x08:
					epsilon = 14645;
					beta = 0;
					UART_field_buffer[7] = epsilon & 0xff;
					UART_field_buffer[8] = (epsilon >> 8) & 0xff;
					UART_field_buffer[9] = beta & 0xff;
					UART_field_buffer[10] = (beta >> 8) & 0xff;
				  break;
				case 0x09:
					epsilon = 15506;
					beta = 0;
					UART_field_buffer[7] = epsilon & 0xff;
					UART_field_buffer[8] = (epsilon >> 8) & 0xff;
					UART_field_buffer[9] = beta & 0xff;
					UART_field_buffer[10] = (beta >> 8) & 0xff;
				  break;
				case 0x0A:
					epsilon = 10338;
					beta = 0;
					UART_field_buffer[7] = epsilon & 0xff;
					UART_field_buffer[8] = (epsilon >> 8) & 0xff;
					UART_field_buffer[9] = beta & 0xff;
					UART_field_buffer[10] = (beta >> 8) & 0xff;
				  break;
				case 0x0B:
					epsilon = 11199;
					beta = 0;
					UART_field_buffer[7] = epsilon & 0xff;
					UART_field_buffer[8] = (epsilon >> 8) & 0xff;
					UART_field_buffer[9] = beta & 0xff;
					UART_field_buffer[10] = (beta >> 8) & 0xff;
				  break;
				case 0x0C:
					epsilon = 12491;
					beta = 0;
					UART_field_buffer[7] = epsilon & 0xff;
					UART_field_buffer[8] = (epsilon >> 8) & 0xff;
					UART_field_buffer[9] = beta & 0xff;
					UART_field_buffer[10] = (beta >> 8) & 0xff;
				  break;
				case 0x0D:
					epsilon = 13353;
					beta = 0;
					UART_field_buffer[7] = epsilon & 0xff;
					UART_field_buffer[8] = (epsilon >> 8) & 0xff;
					UART_field_buffer[9] = beta & 0xff;
					UART_field_buffer[10] = (beta >> 8) & 0xff;
				  break;
				case 0x0E:
					epsilon = 0;
					beta = 0;
					UART_field_buffer[7] = epsilon & 0xff;
					UART_field_buffer[8] = (epsilon >> 8) & 0xff;
					UART_field_buffer[9] = beta & 0xff;
					UART_field_buffer[10] = (beta >> 8) & 0xff;
				  break;
				case 0x0F:
					epsilon = 0;
					beta = 0;
					UART_field_buffer[7] = epsilon & 0xff;
					UART_field_buffer[8] = (epsilon >> 8) & 0xff;
					UART_field_buffer[9] = beta & 0xff;
					UART_field_buffer[10] = (beta >> 8) & 0xff;
				  break;
				case 0x10:
					epsilon = 0;
					beta = 0;
					UART_field_buffer[7] = epsilon & 0xff;
					UART_field_buffer[8] = (epsilon >> 8) & 0xff;
					UART_field_buffer[9] = beta & 0xff;
					UART_field_buffer[10] = (beta >> 8) & 0xff;
				  break;
				case 0x11:
					epsilon = 0;
					beta = 0;
					UART_field_buffer[7] = epsilon & 0xff;
					UART_field_buffer[8] = (epsilon >> 8) & 0xff;
					UART_field_buffer[9] = beta & 0xff;
					UART_field_buffer[10] = (beta >> 8) & 0xff;
				  break;
				case 0x12:
					epsilon = -1738;
					beta = 0;
					UART_field_buffer[7] = epsilon & 0xff;
					UART_field_buffer[8] = (epsilon >> 8) & 0xff;
					UART_field_buffer[9] = beta & 0xff;
					UART_field_buffer[10] = (beta >> 8) & 0xff;
				  break;
				case 0x13:
					epsilon = 1738;
					beta = 0;
					UART_field_buffer[7] = epsilon & 0xff;
					UART_field_buffer[8] = (epsilon >> 8) & 0xff;
					UART_field_buffer[9] = beta & 0xff;
					UART_field_buffer[10] = (beta >> 8) & 0xff;
				  break;
				case 0x14:
					epsilon = 0;
					beta = 1738;
					UART_field_buffer[7] = epsilon & 0xff;
					UART_field_buffer[8] = (epsilon >> 8) & 0xff;
					UART_field_buffer[9] = beta & 0xff;
					UART_field_buffer[10] = (beta >> 8) & 0xff;
				  break;
				case 0x15:
					epsilon = 0;
					beta = -1738;
					UART_field_buffer[7] = epsilon & 0xff;
					UART_field_buffer[8] = (epsilon >> 8) & 0xff;
					UART_field_buffer[9] = beta & 0xff;
					UART_field_buffer[10] = (beta >> 8) & 0xff;
				  break;
				case 0x16:
					epsilon = -1738;
					beta = 0;
					UART_field_buffer[7] = epsilon & 0xff;
					UART_field_buffer[8] = (epsilon >> 8) & 0xff;
					UART_field_buffer[9] = beta & 0xff;
					UART_field_buffer[10] = (beta >> 8) & 0xff;
				  break;
				case 0x17:
					epsilon = 1738;
					beta = 0;
					UART_field_buffer[7] = epsilon & 0xff;
					UART_field_buffer[8] = (epsilon >> 8) & 0xff;
					UART_field_buffer[9] = beta & 0xff;
					UART_field_buffer[10] = (beta >> 8) & 0xff;
				  break;
				case 0x18:
					epsilon = 0;
					beta = 1738;
					UART_field_buffer[7] = epsilon & 0xff;
					UART_field_buffer[8] = (epsilon >> 8) & 0xff;
					UART_field_buffer[9] = beta & 0xff;
					UART_field_buffer[10] = (beta >> 8) & 0xff;
				  break;
				case 0x19:
					epsilon = 0;
					beta = -1738;
					UART_field_buffer[7] = epsilon & 0xff;
					UART_field_buffer[8] = (epsilon >> 8) & 0xff;
					UART_field_buffer[9] = beta & 0xff;
					UART_field_buffer[10] = (beta >> 8) & 0xff;
				  break;
				case 0x1A:
					epsilon = 21537;
					beta = -108;
					UART_field_buffer[7] = epsilon & 0xff;
					UART_field_buffer[8] = (epsilon >> 8) & 0xff;
					UART_field_buffer[9] = beta & 0xff;
					UART_field_buffer[10] = (beta >> 8) & 0xff;
				  break;
				case 0x1B:
					epsilon = 21537;
					beta = -108;
					UART_field_buffer[7] = epsilon & 0xff;
					UART_field_buffer[8] = (epsilon >> 8) & 0xff;
					UART_field_buffer[9] = beta & 0xff;
					UART_field_buffer[10] = (beta >> 8) & 0xff;
				  break;
				case 0x20:
				  break;
				case 0x21:
				  break;
				case 0x22:
				  break;
				case 0x23:
				  break;
				case 0x24:
				  break;
				default:
					UART_field_buffer[7] = 0;
					UART_field_buffer[8] = 0;
					UART_field_buffer[9] = 0;
					UART_field_buffer[10] = 0;
					break;
			}
			UART_field_buffer[11] = 0x00;
			UART_field_buffer[12] = 2;
			UART_field_buffer[13] = 0x00;
			frame_verify = UART_field_buffer[2] + UART_field_buffer[3] + UART_field_buffer[4] + UART_field_buffer[5] + \
										 UART_field_buffer[6] + UART_field_buffer[7] + UART_field_buffer[8] + UART_field_buffer[9] + \
										 UART_field_buffer[10] + UART_field_buffer[11] + UART_field_buffer[12] + UART_field_buffer[13];
			UART_field_buffer[14] = frame_verify & 0xff;
			UART_field_buffer[15] = 0x86;
			HAL_UART_Transmit_DMA(&huart1, (uint8_t *)&UART_field_buffer, 16);   //choose uart line
		}
		//small field
		else {
			UART_field_buffer[0] = 0xA6;
			UART_field_buffer[1] = 0x10;
			UART_field_buffer[2] = 0x81;
			UART_field_buffer[3] = temp_t & 0xff;
			UART_field_buffer[4] = (temp_t >> 8) & 0xff;
			UART_field_buffer[5] = (temp_t >> 16) & 0xff;
			UART_field_buffer[6] = (temp_t >> 24) & 0xff;
			switch (current_command) {
				case 0x1D:
					epsilon = 0;
					beta = -16383;
					UART_field_buffer[7] = epsilon & 0xff;
					UART_field_buffer[8] = (epsilon >> 8) & 0xff;
					UART_field_buffer[9] = beta & 0xff;
					UART_field_buffer[10] = (beta >> 8) & 0xff;
					break;
				case 0x1F:
					epsilon = 0;
					beta = -16383;
					UART_field_buffer[7] = epsilon & 0xff;
					UART_field_buffer[8] = (epsilon >> 8) & 0xff;
					UART_field_buffer[9] = beta & 0xff;
					UART_field_buffer[10] = (beta >> 8) & 0xff;
					break;
				case 0x01:
				  break;
				case 0x02:
				  break;
				case 0x03:
					epsilon = 0;
					beta = 0;
					UART_field_buffer[7] = epsilon & 0xff;
					UART_field_buffer[8] = (epsilon >> 8) & 0xff;
					UART_field_buffer[9] = beta & 0xff;
					UART_field_buffer[10] = (beta >> 8) & 0xff;
				  break;
				case 0x04:
					epsilon = 0;
					beta = 0;
					UART_field_buffer[7] = epsilon & 0xff;
					UART_field_buffer[8] = (epsilon >> 8) & 0xff;
					UART_field_buffer[9] = beta & 0xff;
					UART_field_buffer[10] = (beta >> 8) & 0xff;
				  break;
				case 0x05:
					epsilon = 0;
					beta = 0;
					UART_field_buffer[7] = epsilon & 0xff;
					UART_field_buffer[8] = (epsilon >> 8) & 0xff;
					UART_field_buffer[9] = beta & 0xff;
					UART_field_buffer[10] = (beta >> 8) & 0xff;
				  break;
				case 0x06:
					epsilon = 7864;
					beta = 0;
					UART_field_buffer[7] = epsilon & 0xff;
					UART_field_buffer[8] = (epsilon >> 8) & 0xff;
					UART_field_buffer[9] = beta & 0xff;
					UART_field_buffer[10] = (beta >> 8) & 0xff;
				  break;
				case 0x07:
					epsilon = 8519;
					beta = 0;
					UART_field_buffer[7] = epsilon & 0xff;
					UART_field_buffer[8] = (epsilon >> 8) & 0xff;
					UART_field_buffer[9] = beta & 0xff;
					UART_field_buffer[10] = (beta >> 8) & 0xff;
				  break;
				case 0x08:
					epsilon = 11140;
					beta = 0;
					UART_field_buffer[7] = epsilon & 0xff;
					UART_field_buffer[8] = (epsilon >> 8) & 0xff;
					UART_field_buffer[9] = beta & 0xff;
					UART_field_buffer[10] = (beta >> 8) & 0xff;
				  break;
				case 0x09:
					epsilon = 11796;
					beta = 0;
					UART_field_buffer[7] = epsilon & 0xff;
					UART_field_buffer[8] = (epsilon >> 8) & 0xff;
					UART_field_buffer[9] = beta & 0xff;
					UART_field_buffer[10] = (beta >> 8) & 0xff;
				  break;
				case 0x0A:
					epsilon = 7864;
					beta = 0;
					UART_field_buffer[7] = epsilon & 0xff;
					UART_field_buffer[8] = (epsilon >> 8) & 0xff;
					UART_field_buffer[9] = beta & 0xff;
					UART_field_buffer[10] = (beta >> 8) & 0xff;
				  break;
				case 0x0B:
					epsilon = 8619;
					beta = 0;
					UART_field_buffer[7] = epsilon & 0xff;
					UART_field_buffer[8] = (epsilon >> 8) & 0xff;
					UART_field_buffer[9] = beta & 0xff;
					UART_field_buffer[10] = (beta >> 8) & 0xff;
				  break;
				case 0x0C:
					epsilon = 9502;
					beta = 0;
					UART_field_buffer[7] = epsilon & 0xff;
					UART_field_buffer[8] = (epsilon >> 8) & 0xff;
					UART_field_buffer[9] = beta & 0xff;
					UART_field_buffer[10] = (beta >> 8) & 0xff;
				  break;
				case 0x0D:
					epsilon = 10158;
					beta = 0;
					UART_field_buffer[7] = epsilon & 0xff;
					UART_field_buffer[8] = (epsilon >> 8) & 0xff;
					UART_field_buffer[9] = beta & 0xff;
					UART_field_buffer[10] = (beta >> 8) & 0xff;
				  break;
				case 0x0E:
					epsilon = 0;
					beta = 0;
					UART_field_buffer[7] = epsilon & 0xff;
					UART_field_buffer[8] = (epsilon >> 8) & 0xff;
					UART_field_buffer[9] = beta & 0xff;
					UART_field_buffer[10] = (beta >> 8) & 0xff;
				  break;
				case 0x0F:
					epsilon = 0;
					beta = 0;
					UART_field_buffer[7] = epsilon & 0xff;
					UART_field_buffer[8] = (epsilon >> 8) & 0xff;
					UART_field_buffer[9] = beta & 0xff;
					UART_field_buffer[10] = (beta >> 8) & 0xff;
				  break;
				case 0x10:
					epsilon = 0;
					beta = 0;
					UART_field_buffer[7] = epsilon & 0xff;
					UART_field_buffer[8] = (epsilon >> 8) & 0xff;
					UART_field_buffer[9] = beta & 0xff;
					UART_field_buffer[10] = (beta >> 8) & 0xff;
				  break;
				case 0x11:
					epsilon = 0;
					beta = 0;
					UART_field_buffer[7] = epsilon & 0xff;
					UART_field_buffer[8] = (epsilon >> 8) & 0xff;
					UART_field_buffer[9] = beta & 0xff;
					UART_field_buffer[10] = (beta >> 8) & 0xff;
				  break;
				case 0x12:
					epsilon = -1322;
					beta = 0;
					UART_field_buffer[7] = epsilon & 0xff;
					UART_field_buffer[8] = (epsilon >> 8) & 0xff;
					UART_field_buffer[9] = beta & 0xff;
					UART_field_buffer[10] = (beta >> 8) & 0xff;
				  break;
				case 0x013:
					epsilon = 1322;
					beta = 0;
					UART_field_buffer[7] = epsilon & 0xff;
					UART_field_buffer[8] = (epsilon >> 8) & 0xff;
					UART_field_buffer[9] = beta & 0xff;
					UART_field_buffer[10] = (beta >> 8) & 0xff;
				  break;
				case 0x014:
					epsilon = 0;
					beta = 1322;
					UART_field_buffer[7] = epsilon & 0xff;
					UART_field_buffer[8] = (epsilon >> 8) & 0xff;
					UART_field_buffer[9] = beta & 0xff;
					UART_field_buffer[10] = (beta >> 8) & 0xff;
				  break;
				case 0x15:
					epsilon = 0;
					beta = -1322;
					UART_field_buffer[7] = epsilon & 0xff;
					UART_field_buffer[8] = (epsilon >> 8) & 0xff;
					UART_field_buffer[9] = beta & 0xff;
					UART_field_buffer[10] = (beta >> 8) & 0xff;
				  break;
				case 0x16:
					epsilon = -1322;
					beta = 0;
					UART_field_buffer[7] = epsilon & 0xff;
					UART_field_buffer[8] = (epsilon >> 8) & 0xff;
					UART_field_buffer[9] = beta & 0xff;
					UART_field_buffer[10] = (beta >> 8) & 0xff;
				  break;
				case 0x17:
					epsilon = 1322;
					beta = 0;
					UART_field_buffer[7] = epsilon & 0xff;
					UART_field_buffer[8] = (epsilon >> 8) & 0xff;
					UART_field_buffer[9] = beta & 0xff;
					UART_field_buffer[10] = (beta >> 8) & 0xff;
				  break;
				case 0x18:
					epsilon = 0;
					beta = 1322;
					UART_field_buffer[7] = epsilon & 0xff;
					UART_field_buffer[8] = (epsilon >> 8) & 0xff;
					UART_field_buffer[9] = beta & 0xff;
					UART_field_buffer[10] = (beta >> 8) & 0xff;
				  break;
				case 0x19:
					epsilon = 0;
					beta = -1322;
					UART_field_buffer[7] = epsilon & 0xff;
					UART_field_buffer[8] = (epsilon >> 8) & 0xff;
					UART_field_buffer[9] = beta & 0xff;
					UART_field_buffer[10] = (beta >> 8) & 0xff;
				  break;
				case 0x1A:
					epsilon = 16383;
					beta = -81;
					UART_field_buffer[7] = epsilon & 0xff;
					UART_field_buffer[8] = (epsilon >> 8) & 0xff;
					UART_field_buffer[9] = beta & 0xff;
					UART_field_buffer[10] = (beta >> 8) & 0xff;
				  break;
				case 0x1B:
					epsilon = 16383;
					beta = -81;
					UART_field_buffer[7] = epsilon & 0xff;
					UART_field_buffer[8] = (epsilon >> 8) & 0xff;
					UART_field_buffer[9] = beta & 0xff;
					UART_field_buffer[10] = (beta >> 8) & 0xff;
				  break;
				case 0x20:
				  break;
				case 0x21:
				  break;
				case 0x22:
				  break;
				case 0x23:
				  break;
				case 0x24:
				  break;
				default:
					UART_field_buffer[7] = 0;
					UART_field_buffer[8] = 0;
					UART_field_buffer[9] = 0;
					UART_field_buffer[10] = 0;
					break;
			}
			UART_field_buffer[11] = 0x00;
			UART_field_buffer[12] = 2;
			UART_field_buffer[13] = 0x01;
			frame_verify = UART_field_buffer[2] + UART_field_buffer[3] + UART_field_buffer[4] + UART_field_buffer[5] + \
										 UART_field_buffer[6] + UART_field_buffer[7] + UART_field_buffer[8] + UART_field_buffer[9] + \
										 UART_field_buffer[10] + UART_field_buffer[11] + UART_field_buffer[12] + UART_field_buffer[13];
			UART_field_buffer[14] = frame_verify & 0xff;
			UART_field_buffer[15] = 0x86;
			HAL_UART_Transmit_DMA(&huart1, (uint8_t *)&UART_field_buffer, 16);   //choose uart line
		}
		vTaskDelay(20 * portTICK_RATE_MS);
	} while(xSemaphoreTake( uart_A1_xSemaphore, 0) != pdTRUE);
}

void HAL_UART_RxCpltCallback(UART_HandleTypeDef *UartHandle)
{
	 portBASE_TYPE uart_xHigherPriorityTaskWoken;
	 if(UartHandle->Instance==USART1){
			HAL_UART_Receive_IT(&huart1, (uint8_t*) &ch, 1); 		//write ch
			//cnt = 0 of cnt != 0
		  if (uart_recv_cnt == 0)
			{
				if (ch == 0xA6) {
					UART_recv_buffer[uart_recv_cnt] = ch;
					uart_recv_cnt++;
				}
			}
			else if (uart_recv_cnt != 0)
			{
				UART_recv_buffer[uart_recv_cnt] = ch;
				uart_recv_cnt++;
				if (uart_recv_cnt == 13)
				{
					if ( UART_recv_buffer[12] == 0x86)
					{
						switch ( UART_recv_buffer[2]) {
							case 0x55:
								xSemaphoreGiveFromISR( uart_A1_xSemaphore, &uart_xHigherPriorityTaskWoken );
								uart_recv_cnt = 0;
								break;
							case 0x71:
								switch ( UART_recv_buffer[7]) {
									case 1:
	//									xSemaphoreGiveFromISR( uart_A2_xSemaphore, &xHigherPriorityTaskWoken );
										uart_recv_cnt = 0;
										break;
									case 2:
	//									xSemaphoreGiveFromISR( uart_A3_xSemaphore, &xHigherPriorityTaskWoken );
										uart_recv_cnt = 0;
										break;
									default:
										uart_recv_cnt = 0;
										break;
								}
								break;
							default:
								uart_recv_cnt = 0;
								break;
						}
					}
					else
					{
						uart_recv_cnt = 0;
					}
				}
				else if (uart_recv_cnt > 13)
				{
					uart_recv_cnt = 0;
				}
			}
	 }
}

/* USER CODE END 4 */

void StartDefaultTask(void *argument)
{
  for(;;)
  {
    osDelay(1);
  }
}

void StartBlink(void *argument)
{
  /* USER CODE BEGIN StartBlink */
  /* Infinite loop */
  for(;;)
  {
    osDelay(250);
		HAL_GPIO_TogglePin(GPIOD, LD4_Pin);
  }
  /* USER CODE END StartBlink */
}

void StartKeepState(void *argument)
{
  /* USER CODE BEGIN StartKeepState */
  /* Infinite loop */
  for(;;)
  {
		current_command = (HAL_GPIO_ReadPin(GPIOD, GPIO_PIN_2)<<0) |  \
											(HAL_GPIO_ReadPin(GPIOD, GPIO_PIN_3)<<1) |  \
										  (HAL_GPIO_ReadPin(GPIOD, GPIO_PIN_4)<<2) |  \
										  (HAL_GPIO_ReadPin(GPIOD, GPIO_PIN_7)<<3) |  \
										  (HAL_GPIO_ReadPin(GPIOB, GPIO_PIN_3)<<4) |  \
										  (HAL_GPIO_ReadPin(GPIOB, GPIO_PIN_5)<<5) |  \
										  (HAL_GPIO_ReadPin(GPIOB, GPIO_PIN_8)<<6) |  \
											(HAL_GPIO_ReadPin(GPIOB, GPIO_PIN_9)<<7);
		if (current_command != previous_command)
		{
			previous_command = current_command;
			if (process_command() != HAL_OK )
			{
				Error_Handler();
			}
		}
    osDelay(10);
  }
  /* USER CODE END StartKeepState */
}

void HAL_TIM_PeriodElapsedCallback(TIM_HandleTypeDef *htim)
{
  if (htim->Instance == TIM14) {
    HAL_IncTick();
  }
}

void Error_Handler(void)
{
}

/************************ (C) COPYRIGHT STMicroelectronics *****END OF FILE****/
